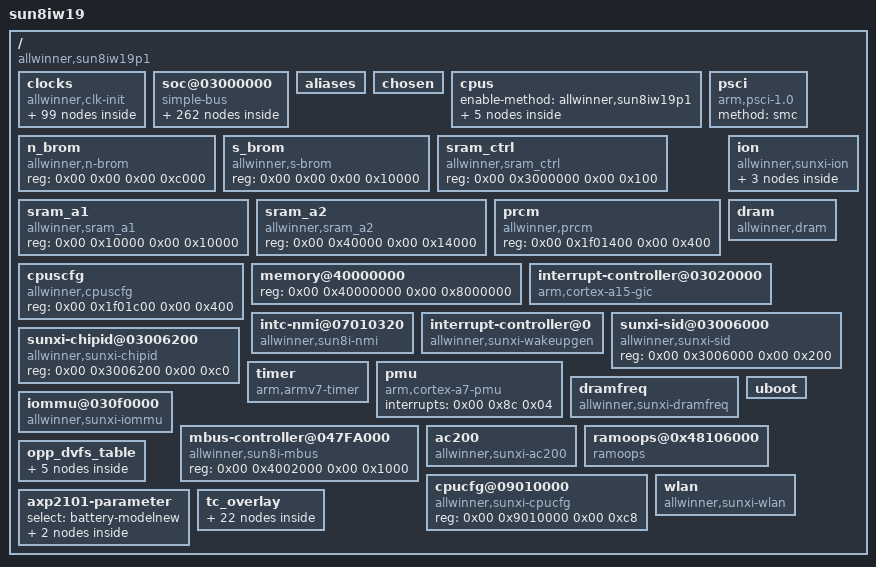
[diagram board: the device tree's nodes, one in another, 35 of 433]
/dts-v1/;

/memreserve/	0x0000000041980000 0x0000000000018000;
/ {
	model = "sun8iw19";
	compatible = "allwinner,sun8iw19p1";
	interrupt-parent = <0x01>;
	#address-cells = <0x02>;
	#size-cells = <0x02>;

	clocks {
		compatible = "allwinner,clk-init";
		device_type = "clocks";
		#address-cells = <0x02>;
		#size-cells = <0x02>;
		ranges;
		reg = <0x00 0x3001000 0x00 0x1000 0x00 0x7010000 0x00 0x400 0x00 0x7000000 0x00 0x200>;

		losc {
			#clock-cells = <0x00>;
			compatible = "allwinner,fixed-clock";
			clock-frequency = <0x8000>;
			clock-output-names = "losc";
			linux,phandle = <0x12>;
			phandle = <0x12>;
		};

		iosc {
			#clock-cells = <0x00>;
			compatible = "allwinner,fixed-clock";
			clock-frequency = <0xf42400>;
			clock-output-names = "iosc";
			linux,phandle = <0xb6>;
			phandle = <0xb6>;
		};

		hosc {
			#clock-cells = <0x00>;
			compatible = "allwinner,fixed-clock";
			clock-frequency = <0x16e3600>;
			clock-output-names = "hosc";
			linux,phandle = <0x08>;
			phandle = <0x08>;
		};

		pll_periph0div25m {
			#clock-cells = <0x00>;
			compatible = "allwinner,fixed-clock";
			clock-frequency = <0x17d7840>;
			clock-output-names = "pll_periph0div25m";
			linux,phandle = <0xb7>;
			phandle = <0xb7>;
		};

		osc48m {
			#clock-cells = <0x00>;
			compatible = "allwinner,fixed-clock";
			clock-frequency = <0x2dc6c00>;
			clock-output-names = "osc48m";
			linux,phandle = <0x09>;
			phandle = <0x09>;
		};

		pll_cpu {
			#clock-cells = <0x00>;
			compatible = "allwinner,pll-clock";
			lock-mode = "new";
			clock-output-names = "pll_cpu";
			linux,phandle = <0xaa>;
			phandle = <0xaa>;
		};

		pll_ddr0 {
			#clock-cells = <0x00>;
			compatible = "allwinner,pll-clock";
			lock-mode = "new";
			clock-output-names = "pll_ddr0";
			linux,phandle = <0x07>;
			phandle = <0x07>;
		};

		pll_periph0 {
			#clock-cells = <0x00>;
			compatible = "allwinner,pll-clock";
			assigned-clock-rates = <0x23c34600>;
			lock-mode = "new";
			clock-output-names = "pll_periph0";
			linux,phandle = <0x05>;
			phandle = <0x05>;
		};

		pll_uni {
			#clock-cells = <0x00>;
			compatible = "allwinner,pll-clock";
			assigned-clocks = <0x02>;
			assigned-clock-rates = <0x35a4e900>;
			lock-mode = "new";
			clock-output-names = "pll_uni";
			linux,phandle = <0x02>;
			phandle = <0x02>;
		};

		pll_video0 {
			#clock-cells = <0x00>;
			compatible = "allwinner,pll-clock";
			lock-mode = "new";
			clock-output-names = "pll_video0";
			linux,phandle = <0x06>;
			phandle = <0x06>;
		};

		pll_audio {
			#clock-cells = <0x00>;
			compatible = "allwinner,pll-clock";
			assigned-clocks = <0x03>;
			assigned-clock-rates = <0x1770000>;
			lock-mode = "new";
			clock-output-names = "pll_audio";
			linux,phandle = <0x03>;
			phandle = <0x03>;
		};

		pll_csi {
			#clock-cells = <0x00>;
			compatible = "allwinner,pll-clock";
			assigned-clocks = <0x04>;
			assigned-clock-rates = <0x202fbf00>;
			lock-mode = "new";
			clock-output-names = "pll_csi";
			linux,phandle = <0x04>;
			phandle = <0x04>;
		};

		pll_periph0x2 {
			#clock-cells = <0x00>;
			compatible = "allwinner,fixed-factor-clock";
			clocks = <0x05>;
			clock-mult = <0x02>;
			clock-div = <0x01>;
			clock-output-names = "pll_periph0x2";
			linux,phandle = <0x0e>;
			phandle = <0x0e>;
		};

		periph32k {
			#clock-cells = <0x00>;
			compatible = "allwinner,fixed-factor-clock";
			clocks = <0x05>;
			clock-mult = <0x02>;
			clock-div = <0x8f0d>;
			clock-output-names = "periph32k";
			linux,phandle = <0xb8>;
			phandle = <0xb8>;
		};

		pll_unix2 {
			#clock-cells = <0x00>;
			compatible = "allwinner,fixed-factor-clock";
			clocks = <0x02>;
			clock-mult = <0x02>;
			clock-div = <0x01>;
			clock-output-names = "pll_unix2";
			linux,phandle = <0x14>;
			phandle = <0x14>;
		};

		pll_audiox4 {
			#clock-cells = <0x00>;
			compatible = "allwinner,fixed-factor-clock";
			clocks = <0x03>;
			clock-mult = <0x04>;
			clock-div = <0x01>;
			clock-output-names = "pll_audiox4";
			linux,phandle = <0xb9>;
			phandle = <0xb9>;
		};

		pll_audiox2 {
			#clock-cells = <0x00>;
			compatible = "allwinner,fixed-factor-clock";
			clocks = <0x03>;
			clock-mult = <0x02>;
			clock-div = <0x01>;
			clock-output-names = "pll_audiox2";
			linux,phandle = <0xba>;
			phandle = <0xba>;
		};

		pll_video0x4 {
			#clock-cells = <0x00>;
			compatible = "allwinner,fixed-factor-clock";
			clocks = <0x06>;
			clock-mult = <0x04>;
			clock-div = <0x01>;
			clock-output-names = "pll_video0x4";
			linux,phandle = <0xbb>;
			phandle = <0xbb>;
		};

		mbus {
			#clock-cells = <0x00>;
			compatible = "allwinner,fixed-factor-clock";
			clocks = <0x07>;
			clock-mult = <0x01>;
			clock-div = <0x04>;
			clock-output-names = "mbus";
			linux,phandle = <0xbc>;
			phandle = <0xbc>;
		};

		hoscd2 {
			#clock-cells = <0x00>;
			compatible = "allwinner,fixed-factor-clock";
			clocks = <0x08>;
			clock-mult = <0x01>;
			clock-div = <0x02>;
			clock-output-names = "hoscd2";
			linux,phandle = <0xbd>;
			phandle = <0xbd>;
		};

		osc48md4 {
			#clock-cells = <0x00>;
			compatible = "allwinner,fixed-factor-clock";
			clocks = <0x09>;
			clock-mult = <0x01>;
			clock-div = <0x04>;
			clock-output-names = "osc48md4";
			linux,phandle = <0x45>;
			phandle = <0x45>;
		};

		cpu {
			#clock-cells = <0x00>;
			compatible = "allwinner,cpu-clock";
			clock-output-names = "cpu";
			linux,phandle = <0xbe>;
			phandle = <0xbe>;
		};

		axi {
			#clock-cells = <0x00>;
			compatible = "allwinner,periph-clock";
			clock-output-names = "axi";
			linux,phandle = <0xbf>;
			phandle = <0xbf>;
		};

		cpuapb {
			#clock-cells = <0x00>;
			compatible = "allwinner,periph-clock";
			clock-output-names = "cpuapb";
			linux,phandle = <0xc0>;
			phandle = <0xc0>;
		};

		psi {
			#clock-cells = <0x00>;
			compatible = "allwinner,periph-clock";
			clock-output-names = "psi";
			linux,phandle = <0xc1>;
			phandle = <0xc1>;
		};

		ahb1 {
			#clock-cells = <0x00>;
			compatible = "allwinner,periph-clock";
			clock-output-names = "ahb1";
			linux,phandle = <0xc2>;
			phandle = <0xc2>;
		};

		ahb2 {
			#clock-cells = <0x00>;
			compatible = "allwinner,periph-clock";
			clock-output-names = "ahb2";
			linux,phandle = <0xc3>;
			phandle = <0xc3>;
		};

		ahb3 {
			#clock-cells = <0x00>;
			compatible = "allwinner,periph-clock";
			clock-output-names = "ahb3";
			linux,phandle = <0xc4>;
			phandle = <0xc4>;
		};

		apb1 {
			#clock-cells = <0x00>;
			compatible = "allwinner,periph-clock";
			clock-output-names = "apb1";
			linux,phandle = <0xc5>;
			phandle = <0xc5>;
		};

		apb2 {
			#clock-cells = <0x00>;
			compatible = "allwinner,periph-clock";
			clock-output-names = "apb2";
			linux,phandle = <0xc6>;
			phandle = <0xc6>;
		};

		de {
			#clock-cells = <0x00>;
			compatible = "allwinner,periph-clock";
			assigned-clocks = <0x0a>;
			assigned-clock-rates = <0x11e1a300>;
			clock-output-names = "de";
			linux,phandle = <0x0a>;
			phandle = <0x0a>;
		};

		g2d {
			#clock-cells = <0x00>;
			compatible = "allwinner,periph-clock";
			assigned-clock-rates = <0x11e1a300>;
			assigned-clocks = <0x0b>;
			clock-output-names = "g2d";
			linux,phandle = <0x0b>;
			phandle = <0x0b>;
		};

		ve {
			#clock-cells = <0x00>;
			compatible = "allwinner,periph-clock";
			assigned-clock-rates = <0x1ad27480>;
			assigned-clocks = <0x0c>;
			clock-output-names = "ve";
			linux,phandle = <0x0c>;
			phandle = <0x0c>;
		};

		ce {
			#clock-cells = <0x00>;
			compatible = "allwinner,periph-clock";
			clock-output-names = "ce";
			linux,phandle = <0x9d>;
			phandle = <0x9d>;
		};

		eise {
			#clock-cells = <0x00>;
			compatible = "allwinner,periph-clock";
			clock-output-names = "eise";
			linux,phandle = <0x16>;
			phandle = <0x16>;
		};

		nna {
			#clock-cells = <0x00>;
			compatible = "allwinner,periph-clock";
			assigned-clocks = <0x0d>;
			assigned-clock-parents = <0x0e>;
			clock-output-names = "nna";
			linux,phandle = <0x0d>;
			phandle = <0x0d>;
		};

		nna_rts {
			#clock-cells = <0x00>;
			compatible = "allwinner,periph-clock";
			clock-output-names = "nna_rst";
			linux,phandle = <0x70>;
			phandle = <0x70>;
		};

		isp {
			#clock-cells = <0x00>;
			compatible = "allwinner,periph-clock";
			clock-output-names = "isp";
			linux,phandle = <0x93>;
			phandle = <0x93>;
		};

		dma {
			#clock-cells = <0x00>;
			compatible = "allwinner,periph-clock";
			clock-output-names = "dma";
			linux,phandle = <0x13>;
			phandle = <0x13>;
		};

		hstimer {
			#clock-cells = <0x00>;
			compatible = "allwinner,periph-clock";
			clock-output-names = "hstimer";
			linux,phandle = <0xc7>;
			phandle = <0xc7>;
		};

		avs {
			#clock-cells = <0x00>;
			compatible = "allwinner,periph-clock";
			clock-output-names = "avs";
			linux,phandle = <0xc8>;
			phandle = <0xc8>;
		};

		dbgsys {
			#clock-cells = <0x00>;
			compatible = "allwinner,periph-clock";
			clock-output-names = "dbgsys";
			linux,phandle = <0xc9>;
			phandle = <0xc9>;
		};

		pwm {
			#clock-cells = <0x00>;
			compatible = "allwinner,periph-clock";
			clock-output-names = "pwm";
			linux,phandle = <0x71>;
			phandle = <0x71>;
		};

		iommu {
			#clock-cells = <0x00>;
			compatible = "allwinner,periph-clock";
			clock-output-names = "iommu";
			linux,phandle = <0xb0>;
			phandle = <0xb0>;
		};

		sdram {
			#clock-cells = <0x00>;
			compatible = "allwinner,periph-clock";
			clock-output-names = "sdram";
			linux,phandle = <0xca>;
			phandle = <0xca>;
		};

		sdmmc0_mod {
			#clock-cells = <0x00>;
			compatible = "allwinner,periph-clock";
			clock-output-names = "sdmmc0_mod";
			linux,phandle = <0x62>;
			phandle = <0x62>;
		};

		sdmmc0_bus {
			#clock-cells = <0x00>;
			compatible = "allwinner,periph-clock";
			clock-output-names = "sdmmc0_bus";
			linux,phandle = <0x63>;
			phandle = <0x63>;
		};

		sdmmc0_rst {
			#clock-cells = <0x00>;
			compatible = "allwinner,periph-clock";
			clock-output-names = "sdmmc0_rst";
			linux,phandle = <0x64>;
			phandle = <0x64>;
		};

		sdmmc1_mod {
			#clock-cells = <0x00>;
			compatible = "allwinner,periph-clock";
			clock-output-names = "sdmmc1_mod";
			linux,phandle = <0x68>;
			phandle = <0x68>;
		};

		sdmmc1_bus {
			#clock-cells = <0x00>;
			compatible = "allwinner,periph-clock";
			clock-output-names = "sdmmc1_bus";
			linux,phandle = <0x69>;
			phandle = <0x69>;
		};

		sdmmc1_rst {
			#clock-cells = <0x00>;
			compatible = "allwinner,periph-clock";
			clock-output-names = "sdmmc1_rst";
			linux,phandle = <0x6a>;
			phandle = <0x6a>;
		};

		sdmmc2_mod {
			#clock-cells = <0x00>;
			compatible = "allwinner,periph-clock";
			clock-output-names = "sdmmc2_mod";
			linux,phandle = <0x5c>;
			phandle = <0x5c>;
		};

		sdmmc2_bus {
			#clock-cells = <0x00>;
			compatible = "allwinner,periph-clock";
			clock-output-names = "sdmmc2_bus";
			linux,phandle = <0x5d>;
			phandle = <0x5d>;
		};

		sdmmc2_rst {
			#clock-cells = <0x00>;
			compatible = "allwinner,periph-clock";
			clock-output-names = "sdmmc2_rst";
			linux,phandle = <0x5e>;
			phandle = <0x5e>;
		};

		uart0 {
			#clock-cells = <0x00>;
			compatible = "allwinner,periph-clock";
			clock-output-names = "uart0";
			linux,phandle = <0x17>;
			phandle = <0x17>;
		};

		uart1 {
			#clock-cells = <0x00>;
			compatible = "allwinner,periph-clock";
			clock-output-names = "uart1";
			linux,phandle = <0x1a>;
			phandle = <0x1a>;
		};

		uart2 {
			#clock-cells = <0x00>;
			compatible = "allwinner,periph-clock";
			clock-output-names = "uart2";
			linux,phandle = <0x1d>;
			phandle = <0x1d>;
		};

		uart3 {
			#clock-cells = <0x00>;
			compatible = "allwinner,periph-clock";
			clock-output-names = "uart3";
			linux,phandle = <0x20>;
			phandle = <0x20>;
		};

		twi0 {
			#clock-cells = <0x00>;
			compatible = "allwinner,periph-clock";
			clock-output-names = "twi0";
			linux,phandle = <0x26>;
			phandle = <0x26>;
		};

		twi1 {
			#clock-cells = <0x00>;
			compatible = "allwinner,periph-clock";
			clock-output-names = "twi1";
			linux,phandle = <0x29>;
			phandle = <0x29>;
		};

		twi2 {
			#clock-cells = <0x00>;
			compatible = "allwinner,periph-clock";
			clock-output-names = "twi2";
			linux,phandle = <0x2c>;
			phandle = <0x2c>;
		};

		twi3 {
			#clock-cells = <0x00>;
			compatible = "allwinner,periph-clock";
			clock-output-names = "twi3";
			linux,phandle = <0x2f>;
			phandle = <0x2f>;
		};

		spi0 {
			#clock-cells = <0x00>;
			compatible = "allwinner,periph-clock";
			clock-output-names = "spi0";
			linux,phandle = <0x50>;
			phandle = <0x50>;
		};

		spi1 {
			#clock-cells = <0x00>;
			compatible = "allwinner,periph-clock";
			clock-output-names = "spi1";
			linux,phandle = <0x54>;
			phandle = <0x54>;
		};

		spi2 {
			#clock-cells = <0x00>;
			compatible = "allwinner,periph-clock";
			clock-output-names = "spi2";
			linux,phandle = <0x58>;
			phandle = <0x58>;
		};

		ephy_25m {
			#clock-cells = <0x00>;
			compatible = "allwinner,periph-clock";
			clock-output-names = "ephy_25m";
			linux,phandle = <0xa7>;
			phandle = <0xa7>;
		};

		gmac {
			#clock-cells = <0x00>;
			compatible = "allwinner,periph-clock";
			clock-output-names = "gmac";
			linux,phandle = <0xa6>;
			phandle = <0xa6>;
		};

		gpadc {
			#clock-cells = <0x00>;
			compatible = "allwinner,periph-clock";
			clock-output-names = "gpadc";
			linux,phandle = <0xa5>;
			phandle = <0xa5>;
		};

		ths {
			#clock-cells = <0x00>;
			compatible = "allwinner,periph-clock";
			clock-output-names = "ths";
			linux,phandle = <0x9e>;
			phandle = <0x9e>;
		};

		i2s0 {
			#clock-cells = <0x00>;
			compatible = "allwinner,periph-clock";
			clock-output-names = "i2s0";
			linux,phandle = <0x46>;
			phandle = <0x46>;
		};

		i2s1 {
			#clock-cells = <0x00>;
			compatible = "allwinner,periph-clock";
			clock-output-names = "i2s1";
			linux,phandle = <0x49>;
			phandle = <0x49>;
		};

		codec_1x {
			#clock-cells = <0x00>;
			compatible = "allwinner,periph-clock";
			clock-output-names = "codec_1x";
			linux,phandle = <0x4c>;
			phandle = <0x4c>;
		};

		codec_4x {
			#clock-cells = <0x00>;
			compatible = "allwinner,periph-clock";
			clock-output-names = "codec_4x";
			linux,phandle = <0xcb>;
			phandle = <0xcb>;
		};

		usbphy0 {
			#clock-cells = <0x00>;
			compatible = "allwinner,periph-clock";
			clock-output-names = "usbphy0";
			linux,phandle = <0x40>;
			phandle = <0x40>;
		};

		usbohci0 {
			#clock-cells = <0x00>;
			compatible = "allwinner,periph-clock";
			clock-output-names = "usbohci0";
			linux,phandle = <0x43>;
			phandle = <0x43>;
		};

		usbohci0_12m {
			#clock-cells = <0x00>;
			compatible = "allwinner,periph-clock";
			clock-output-names = "usbohci0_12m";
			linux,phandle = <0x44>;
			phandle = <0x44>;
		};

		usbehci0 {
			#clock-cells = <0x00>;
			compatible = "allwinner,periph-clock";
			clock-output-names = "usbehci0";
			linux,phandle = <0x42>;
			phandle = <0x42>;
		};

		usbotg {
			#clock-cells = <0x00>;
			compatible = "allwinner,periph-clock";
			clock-output-names = "usbotg";
			linux,phandle = <0x41>;
			phandle = <0x41>;
		};

		mipi_dphy0 {
			#clock-cells = <0x00>;
			compatible = "allwinner,periph-clock";
			clock-output-names = "mipi_dphy0";
			linux,phandle = <0x6f>;
			phandle = <0x6f>;
		};

		mipi_host0 {
			#clock-cells = <0x00>;
			compatible = "allwinner,periph-clock";
			assigned-clocks = <0x0f>;
			assigned-clock-parents = <0x08>;
			clock-output-names = "mipi_host0";
			linux,phandle = <0x0f>;
			phandle = <0x0f>;
		};

		display_top {
			#clock-cells = <0x00>;
			compatible = "allwinner,periph-clock";
			clock-output-names = "display_top";
			linux,phandle = <0x6d>;
			phandle = <0x6d>;
		};

		tcon_lcd {
			#clock-cells = <0x00>;
			compatible = "allwinner,periph-clock";
			clock-output-names = "tcon_lcd";
			linux,phandle = <0x6e>;
			phandle = <0x6e>;
		};

		csi_top {
			#clock-cells = <0x00>;
			compatible = "allwinner,periph-clock";
			clock-output-names = "csi_top";
			linux,phandle = <0x90>;
			phandle = <0x90>;
		};

		csi_master0 {
			#clock-cells = <0x00>;
			compatible = "allwinner,periph-clock";
			clock-output-names = "csi_master0";
			linux,phandle = <0x91>;
			phandle = <0x91>;
		};

		csi_master1 {
			#clock-cells = <0x00>;
			compatible = "allwinner,periph-clock";
			clock-output-names = "csi_master1";
			linux,phandle = <0x92>;
			phandle = <0x92>;
		};

		dspo {
			#clock-cells = <0x00>;
			compatible = "allwinner,periph-clock";
			clock-output-names = "dspo";
			linux,phandle = <0xcc>;
			phandle = <0xcc>;
		};

		pio {
			#clock-cells = <0x00>;
			compatible = "allwinner,periph-clock";
			clock-output-names = "pio";
			linux,phandle = <0x11>;
			phandle = <0x11>;
		};

		cpurowc {
			#clock-cells = <0x00>;
			compatible = "allwinner,periph-cpus-clock";
			clock-output-names = "cpurowc";
			linux,phandle = <0x23>;
			phandle = <0x23>;
		};

		stwi {
			#clock-cells = <0x00>;
			compatible = "allwinner,periph-cpus-clock";
			clock-output-names = "stwi";
			linux,phandle = <0x32>;
			phandle = <0x32>;
		};

		losc_out {
			#clock-cells = <0x00>;
			compatible = "allwinner,periph-cpus-clock";
			clock-output-names = "losc_out";
			linux,phandle = <0xcd>;
			phandle = <0xcd>;
		};

		cpurcpus_pll {
			#clock-cells = <0x00>;
			compatible = "allwinner,periph-cpus-clock";
			clock-output-names = "cpurcpus_pll";
			linux,phandle = <0xce>;
			phandle = <0xce>;
		};

		cpurcpus {
			#clock-cells = <0x00>;
			compatible = "allwinner,periph-cpus-clock";
			clock-output-names = "cpurcpus";
			linux,phandle = <0xcf>;
			phandle = <0xcf>;
		};

		cpurahbs {
			#clock-cells = <0x00>;
			compatible = "allwinner,periph-cpus-clock";
			clock-output-names = "cpurahbs";
			linux,phandle = <0xd0>;
			phandle = <0xd0>;
		};

		cpurapbs1 {
			#clock-cells = <0x00>;
			compatible = "allwinner,periph-cpus-clock";
			clock-output-names = "cpurapbs1";
			linux,phandle = <0xd1>;
			phandle = <0xd1>;
		};

		cpurapbs2_pll {
			#clock-cells = <0x00>;
			compatible = "allwinner,periph-cpus-clock";
			clock-output-names = "cpurapbs2_pll";
			linux,phandle = <0xd2>;
			phandle = <0xd2>;
		};

		cpurapbs2 {
			#clock-cells = <0x00>;
			compatible = "allwinner,periph-cpus-clock";
			clock-output-names = "cpurapbs2";
			linux,phandle = <0xd3>;
			phandle = <0xd3>;
		};

		cpurpio {
			#clock-cells = <0x00>;
			compatible = "allwinner,periph-cpus-clock";
			clock-output-names = "cpurpio";
			linux,phandle = <0x10>;
			phandle = <0x10>;
		};

		spwm {
			#clock-cells = <0x00>;
			compatible = "allwinner,periph-cpus-clock";
			clock-output-names = "spwm";
			linux,phandle = <0xd4>;
			phandle = <0xd4>;
		};

		dcxo_out {
			#clock-cells = <0x00>;
			compatible = "allwinner,periph-cpus-clock";
			clock-output-names = "dcxo_out";
			linux,phandle = <0xb1>;
			phandle = <0xb1>;
		};
	};

	soc@03000000 {
		compatible = "simple-bus";
		#address-cells = <0x02>;
		#size-cells = <0x02>;
		ranges;
		device_type = "soc";
		linux,phandle = <0xb4>;
		phandle = <0xb4>;

		pinctrl@07022000 {
			compatible = "allwinner,sun8iw19p1-r-pinctrl";
			reg = <0x00 0x7022000 0x00 0x400>;
			interrupts = <0x00 0x6a 0x04>;
			clocks = <0x10>;
			device_type = "r_pio";
			gpio-controller;
			interrupt-controller;
			#interrupt-cells = <0x03>;
			#size-cells = <0x00>;
			#gpio-cells = <0x06>;
			linux,phandle = <0xd5>;
			phandle = <0xd5>;

			s_twi0@0 {
				allwinner,pins = "PL0\0PL1";
				allwinner,function = "s_twi0";
				allwinner,muxsel = <0x03>;
				allwinner,drive = <0x01>;
				allwinner,pull = <0x01>;
				linux,phandle = <0x33>;
				phandle = <0x33>;
			};

			s_twi0@1 {
				allwinner,pins = "PL0\0PL1";
				allwinner,function = "io_disabled";
				allwinner,muxsel = <0x07>;
				allwinner,drive = <0x01>;
				allwinner,pull = <0x00>;
				linux,phandle = <0x34>;
				phandle = <0x34>;
			};
		};

		pinctrl@0300b000 {
			compatible = "allwinner,sun8iw19p1-pinctrl";
			reg = <0x00 0x300b000 0x00 0x400>;
			interrupts = <0x00 0x43 0x04 0x00 0x44 0x04 0x00 0x45 0x04 0x00 0x46 0x04 0x00 0x47 0x04 0x00 0x48 0x04 0x00 0x49 0x04>;
			device_type = "pio";
			clocks = <0x11 0x12 0x08>;
			gpio-controller;
			interrupt-controller;
			#interrupt-cells = <0x03>;
			#size-cells = <0x00>;
			#gpio-cells = <0x06>;
			input-debounce = <0x00 0x00 0x00 0x01 0x00 0x00 0x00>;
			linux,phandle = <0x36>;
			phandle = <0x36>;

			vdevice@0 {
				allwinner,pins = "PC0\0PC1";
				allwinner,function = "vdevice";
				allwinner,muxsel = <0x05>;
				allwinner,drive = <0x01>;
				allwinner,pull = <0x01>;
				linux,phandle = <0x9c>;
				phandle = <0x9c>;
			};

			uart0@0 {
				allwinner,pins = "PH9\0PH10";
				allwinner,pname = "uart0_tx\0uart0_rx";
				allwinner,function = "uart0";
				allwinner,muxsel = <0x05>;
				allwinner,drive = <0x01>;
				allwinner,pull = <0x01>;
				linux,phandle = <0x18>;
				phandle = <0x18>;
			};

			uart0@1 {
				allwinner,pins = "PH9\0PH10";
				allwinner,function = "io_disabled";
				allwinner,muxsel = <0x07>;
				allwinner,drive = <0x01>;
				allwinner,pull = <0x00>;
				linux,phandle = <0x19>;
				phandle = <0x19>;
			};

			uart1@0 {
				allwinner,pins = "PG6\0PG7\0PG4\0PG5";
				allwinner,pname = "uart1_tx\0uart1_rx\0uart1_rts\0uart1_cts";
				allwinner,function = "uart1";
				allwinner,muxsel = <0x05>;
				allwinner,drive = <0x01>;
				allwinner,pull = <0x01>;
				linux,phandle = <0x1b>;
				phandle = <0x1b>;
			};

			uart1@1 {
				allwinner,pins = "PG6\0PG7\0PG4\0PG5";
				allwinner,function = "io_disabled";
				allwinner,muxsel = <0x07>;
				allwinner,drive = <0x01>;
				allwinner,pull = <0x00>;
				linux,phandle = <0x1c>;
				phandle = <0x1c>;
			};

			uart3@0 {
				allwinner,pins = "PG0\0PG1\0PG2\0PG3";
				allwinner,pname = "uart3_tx\0uart3_rx\0uart3_rts\0uart3_cts";
				allwinner,function = "uart3";
				allwinner,muxsel = <0x05>;
				allwinner,drive = <0x01>;
				allwinner,pull = <0x01>;
				linux,phandle = <0x21>;
				phandle = <0x21>;
			};

			uart3@1 {
				allwinner,pins = "PG0\0PG1\0PG2\0PG3";
				allwinner,function = "io_disabled";
				allwinner,muxsel = <0x07>;
				allwinner,drive = <0x01>;
				allwinner,pull = <0x00>;
				linux,phandle = <0x22>;
				phandle = <0x22>;
			};

			twi0@0 {
				allwinner,pins = "PE16\0PE17";
				allwinner,pname = "twi0_scl\0twi0_sda";
				allwinner,function = "twi0";
				allwinner,muxsel = <0x05>;
				allwinner,drive = <0x01>;
				allwinner,pull = <0x00>;
				linux,phandle = <0x27>;
				phandle = <0x27>;
			};

			twi0@1 {
				allwinner,pins = "PE16\0PE17";
				allwinner,function = "io_disabled";
				allwinner,muxsel = <0x07>;
				allwinner,drive = <0x01>;
				allwinner,pull = <0x00>;
				linux,phandle = <0x28>;
				phandle = <0x28>;
			};

			twi1@0 {
				allwinner,pins = "PI1\0PI2";
				allwinner,pname = "twi1_scl\0twi1_sda";
				allwinner,function = "twi1";
				allwinner,muxsel = <0x05>;
				allwinner,drive = <0x01>;
				allwinner,pull = <0x00>;
				linux,phandle = <0x2a>;
				phandle = <0x2a>;
			};

			twi1@1 {
				allwinner,pins = "PI1\0PI2";
				allwinner,function = "io_disabled";
				allwinner,muxsel = <0x07>;
				allwinner,drive = <0x01>;
				allwinner,pull = <0x00>;
				linux,phandle = <0x2b>;
				phandle = <0x2b>;
			};

			twi2@0 {
				allwinner,pins = "PH11\0PH12";
				allwinner,pname = "twi2_scl\0twi2_sda";
				allwinner,function = "twi2";
				allwinner,muxsel = <0x05>;
				allwinner,drive = <0x01>;
				allwinner,pull = <0x00>;
				linux,phandle = <0x2d>;
				phandle = <0x2d>;
			};

			twi2@1 {
				allwinner,pins = "PH11\0PH12";
				allwinner,function = "io_disabled";
				allwinner,muxsel = <0x07>;
				allwinner,drive = <0x01>;
				allwinner,pull = <0x00>;
				linux,phandle = <0x2e>;
				phandle = <0x2e>;
			};

			twi3@0 {
				allwinner,pins = "PH13\0PH14";
				allwinner,pname = "twi3_scl\0twi3_sda";
				allwinner,function = "twi3";
				allwinner,muxsel = <0x05>;
				allwinner,drive = <0x01>;
				allwinner,pull = <0x00>;
				linux,phandle = <0x30>;
				phandle = <0x30>;
			};

			twi3@1 {
				allwinner,pins = "PH13\0PH14";
				allwinner,function = "io_disabled";
				allwinner,muxsel = <0x07>;
				allwinner,drive = <0x01>;
				allwinner,pull = <0x00>;
				linux,phandle = <0x31>;
				phandle = <0x31>;
			};

			pwm0@0 {
				allwinner,pins = "PD1";
				allwinner,pname = "pwm0_positive";
				allwinner,function = "pwm0";
				allwinner,muxsel = <0x03>;
				allwinner,drive = <0x01>;
				allwinner,pull = <0x00>;
				linux,phandle = <0x7c>;
				phandle = <0x7c>;
			};

			pwm0@1 {
				allwinner,pins = "PD1";
				allwinner,function = "io_disabled";
				allwinner,muxsel = <0x07>;
				allwinner,drive = <0x01>;
				allwinner,pull = <0x00>;
				linux,phandle = <0x7d>;
				phandle = <0x7d>;
			};

			pwm1@0 {
				allwinner,pins = "PD2";
				allwinner,pname = "pwm1_positive";
				allwinner,function = "pwm1";
				allwinner,muxsel = <0x03>;
				allwinner,drive = <0x01>;
				allwinner,pull = <0x00>;
				linux,phandle = <0x7e>;
				phandle = <0x7e>;
			};

			pwm1@1 {
				allwinner,pins = "PD2";
				allwinner,function = "io_disabled";
				allwinner,muxsel = <0x07>;
				allwinner,drive = <0x01>;
				allwinner,pull = <0x00>;
				linux,phandle = <0x7f>;
				phandle = <0x7f>;
			};

			pwm2@0 {
				allwinner,pins = "PD3";
				allwinner,pname = "pwm2_positive";
				allwinner,function = "pwm2";
				allwinner,muxsel = <0x03>;
				allwinner,drive = <0x01>;
				allwinner,pull = <0x00>;
				linux,phandle = <0x80>;
				phandle = <0x80>;
			};

			pwm2@1 {
				allwinner,pins = "PD3";
				allwinner,function = "io_disabled";
				allwinner,muxsel = <0x07>;
				allwinner,drive = <0x01>;
				allwinner,pull = <0x00>;
				linux,phandle = <0x81>;
				phandle = <0x81>;
			};

			pwm3@0 {
				allwinner,pins = "PD4";
				allwinner,pname = "pwm3_positive";
				allwinner,function = "pwm3";
				allwinner,muxsel = <0x03>;
				allwinner,drive = <0x01>;
				allwinner,pull = <0x00>;
				linux,phandle = <0x82>;
				phandle = <0x82>;
			};

			pwm3@1 {
				allwinner,pins = "PD4";
				allwinner,function = "io_disabled";
				allwinner,muxsel = <0x07>;
				allwinner,drive = <0x01>;
				allwinner,pull = <0x00>;
				linux,phandle = <0x83>;
				phandle = <0x83>;
			};

			pwm4@0 {
				allwinner,pins = "PD5";
				allwinner,pname = "pwm4_positive";
				allwinner,function = "pwm4";
				allwinner,muxsel = <0x03>;
				allwinner,drive = <0x01>;
				allwinner,pull = <0x00>;
				linux,phandle = <0x84>;
				phandle = <0x84>;
			};

			pwm4@1 {
				allwinner,pins = "PD5";
				allwinner,function = "io_disabled";
				allwinner,muxsel = <0x07>;
				allwinner,drive = <0x01>;
				allwinner,pull = <0x00>;
				linux,phandle = <0x85>;
				phandle = <0x85>;
			};

			pwm5@0 {
				allwinner,pins = "PD6";
				allwinner,pname = "pwm5_positive";
				allwinner,function = "pwm5";
				allwinner,muxsel = <0x03>;
				allwinner,drive = <0x01>;
				allwinner,pull = <0x00>;
				linux,phandle = <0x86>;
				phandle = <0x86>;
			};

			pwm5@1 {
				allwinner,pins = "PD6";
				allwinner,function = "io_disabled";
				allwinner,muxsel = <0x07>;
				allwinner,drive = <0x01>;
				allwinner,pull = <0x00>;
				linux,phandle = <0x87>;
				phandle = <0x87>;
			};

			pwm6@0 {
				allwinner,pins = "PD7";
				allwinner,pname = "pwm6_positive";
				allwinner,function = "pwm6";
				allwinner,muxsel = <0x03>;
				allwinner,drive = <0x01>;
				allwinner,pull = <0x00>;
				linux,phandle = <0x88>;
				phandle = <0x88>;
			};

			pwm6@1 {
				allwinner,pins = "PD7";
				allwinner,function = "io_disabled";
				allwinner,muxsel = <0x07>;
				allwinner,drive = <0x01>;
				allwinner,pull = <0x00>;
				linux,phandle = <0x89>;
				phandle = <0x89>;
			};

			pwm7@0 {
				allwinner,pins = "PD8";
				allwinner,pname = "pwm7_positive";
				allwinner,function = "pwm7";
				allwinner,muxsel = <0x03>;
				allwinner,drive = <0x01>;
				allwinner,pull = <0x00>;
				linux,phandle = <0x8a>;
				phandle = <0x8a>;
			};

			pwm7@1 {
				allwinner,pins = "PD8";
				allwinner,function = "io_disabled";
				allwinner,muxsel = <0x07>;
				allwinner,drive = <0x01>;
				allwinner,pull = <0x00>;
				linux,phandle = <0x8b>;
				phandle = <0x8b>;
			};

			pwm8@0 {
				allwinner,pins = "PD9";
				allwinner,pname = "pwm8_positive";
				allwinner,function = "pwm8";
				allwinner,muxsel = <0x03>;
				allwinner,drive = <0x01>;
				allwinner,pull = <0x00>;
				linux,phandle = <0x8c>;
				phandle = <0x8c>;
			};

			pwm8@1 {
				allwinner,pins = "PD9";
				allwinner,function = "io_disabled";
				allwinner,muxsel = <0x07>;
				allwinner,drive = <0x01>;
				allwinner,pull = <0x00>;
				linux,phandle = <0x8d>;
				phandle = <0x8d>;
			};

			pwm9@0 {
				allwinner,pins = "PD22";
				allwinner,pname = "pwm9_positive";
				allwinner,function = "pwm9";
				allwinner,muxsel = <0x02>;
				allwinner,drive = <0x01>;
				allwinner,pull = <0x00>;
				linux,phandle = <0x8e>;
				phandle = <0x8e>;
			};

			pwm9@1 {
				allwinner,pins = "PD22";
				allwinner,function = "io_disabled";
				allwinner,muxsel = <0x07>;
				allwinner,drive = <0x01>;
				allwinner,pull = <0x00>;
				linux,phandle = <0x8f>;
				phandle = <0x8f>;
			};

			ts0@0 {
				allwinner,pins = "PE0\0PE1\0PE2\0PE3\0PE4\0PE5\0PE6\0PE7\0PE8\0PE9\0PE10\0PE11";
				allwinner,pname = "ts0_clk\0ts0_err\0ts0_sync\0ts0_dvld\0ts0_d0\0ts0_d1\0ts0_d2\0ts0_d3\0ts0_d4\0ts0_d5\0ts0_d6\0ts0_d7";
				allwinner,function = "ts0";
				allwinner,muxsel = <0x03>;
				allwinner,drive = <0x01>;
				allwinner,pull = <0x00>;
				linux,phandle = <0xd6>;
				phandle = <0xd6>;
			};

			ts0_sleep@0 {
				allwinner,pins = "PE0\0PE1\0PE2\0PE3\0PE4\0PE5\0PE6\0PE7\0PE8\0PE9\0PE10\0PE11";
				allwinner,pname = "ts0_clk\0ts0_err\0ts0_sync\0ts0_dvld\0ts0_d0\0ts0_d1\0ts0_d2\0ts0_d3\0ts0_d4\0ts0_d5\0ts0_d6\0ts0_d7";
				allwinner,function = "io_disabled";
				allwinner,muxsel = <0x07>;
				allwinner,drive = <0x01>;
				allwinner,pull = <0x00>;
				linux,phandle = <0xd7>;
				phandle = <0xd7>;
			};

			ts1@0 {
				allwinner,pins = "PE7\0PE8\0PE9\0PE10\0PE11";
				allwinner,pname = "ts1_clk\0ts1_err\0ts1_sync\0ts1_dvld\0ts1_d0";
				allwinner,function = "ts1";
				allwinner,muxsel = <0x04>;
				allwinner,drive = <0x01>;
				allwinner,pull = <0x00>;
				linux,phandle = <0xd8>;
				phandle = <0xd8>;
			};

			ts1_sleep@0 {
				allwinner,pins = "PE7\0PE8\0PE9\0PE10\0PE11";
				allwinner,pname = "ts1_clk\0ts1_err\0ts1_sync\0ts1_dvld\0ts1_d0";
				allwinner,function = "io_disabled";
				allwinner,muxsel = <0x07>;
				allwinner,drive = <0x01>;
				allwinner,pull = <0x00>;
				linux,phandle = <0xd9>;
				phandle = <0xd9>;
			};

			ts2@0 {
				allwinner,pins = "PD0\0PD1\0PD2\0PD3\0PD4\0PD5\0PD6\0PD7\0PD8\0PD9\0PD10\0PD11";
				allwinner,pname = "ts2_clk\0ts2_err\0ts2_sync\0ts2_dvld\0ts2_d0\0ts2_d1\0ts2_d2\0ts2_d3\0ts2_d4\0ts2_d5\0ts2_d6\0ts2_d7";
				allwinner,function = "ts2";
				allwinner,muxsel = <0x04>;
				allwinner,drive = <0x01>;
				allwinner,pull = <0x00>;
				linux,phandle = <0xda>;
				phandle = <0xda>;
			};

			ts2_sleep@0 {
				allwinner,pins = "PD0\0PD1\0PD2\0PD3\0PD4\0PD5\0PD6\0PD7\0PD8\0PD9\0PD10\0PD11";
				allwinner,pname = "ts2_clk\0ts2_err\0ts2_sync\0ts2_dvld\0ts2_d0\0ts2_d1\0ts2_d2\0ts2_d3\0ts2_d4\0ts2_d5\0ts2_d6\0ts2_d7";
				allwinner,function = "io_disabled";
				allwinner,muxsel = <0x07>;
				allwinner,drive = <0x01>;
				allwinner,pull = <0x00>;
				linux,phandle = <0xdb>;
				phandle = <0xdb>;
			};

			ts3@0 {
				allwinner,pins = "PD7\0PD8\0PD9\0PD10\0PD11";
				allwinner,pname = "ts3_clk\0ts3_err\0ts3_sync\0ts3_dvld\0ts3_d0";
				allwinner,function = "ts3";
				allwinner,muxsel = <0x05>;
				allwinner,drive = <0x01>;
				allwinner,pull = <0x00>;
				linux,phandle = <0xdc>;
				phandle = <0xdc>;
			};

			ts3_sleep@0 {
				allwinner,pins = "PD7\0PD8\0PD9\0PD10\0PD11";
				allwinner,pname = "ts3_clk\0ts3_err\0ts3_sync\0ts3_dvld\0ts3_d0";
				allwinner,function = "io_disabled";
				allwinner,muxsel = <0x07>;
				allwinner,drive = <0x01>;
				allwinner,pull = <0x00>;
				linux,phandle = <0xdd>;
				phandle = <0xdd>;
			};

			spi0@0 {
				allwinner,pins = "PC0\0PC2\0PC3\0PC5\0PC4";
				allwinner,pname = "spi0_sclk\0spi0_mosi\0spi0_miso\0spi0_hold\0spi0_wp";
				allwinner,function = "spi0";
				allwinner,muxsel = <0x04>;
				allwinner,drive = <0x01>;
				allwinner,pull = <0x00>;
				linux,phandle = <0x51>;
				phandle = <0x51>;
			};

			spi0@1 {
				allwinner,pins = "PC1\0PC6";
				allwinner,pname = "spi0_cs0\0spi0_cs1";
				allwinner,function = "spi0";
				allwinner,muxsel = <0x04>;
				allwinner,drive = <0x01>;
				allwinner,pull = <0x01>;
				linux,phandle = <0x52>;
				phandle = <0x52>;
			};

			spi0@2 {
				allwinner,pins = "PC0\0PC1\0PC2\0PC3\0PC4\0PC5\0PC6";
				allwinner,function = "io_disabled";
				allwinner,muxsel = <0x07>;
				allwinner,drive = <0x01>;
				allwinner,pull = <0x00>;
				linux,phandle = <0x53>;
				phandle = <0x53>;
			};

			spi1@0 {
				allwinner,pins = "PH1\0PH2";
				allwinner,pname = "spi1_sclk\0spi1_mosi\0spi1_miso";
				allwinner,function = "spi1";
				allwinner,muxsel = <0x04>;
				allwinner,drive = <0x01>;
				allwinner,pull = <0x00>;
				linux,phandle = <0x55>;
				phandle = <0x55>;
			};

			spi1@1 {
				allwinner,pins = "PH3\0PH4";
				allwinner,pname = "spi1_cs0\0spi1_cs1";
				allwinner,function = "spi1";
				allwinner,muxsel = <0x04>;
				allwinner,drive = <0x01>;
				allwinner,pull = <0x01>;
				linux,phandle = <0x56>;
				phandle = <0x56>;
			};

			spi1@2 {
				allwinner,pins = "PH1\0PH2\0PH3\0PH4";
				allwinner,function = "io_disabled";
				allwinner,muxsel = <0x07>;
				allwinner,drive = <0x01>;
				allwinner,pull = <0x00>;
				linux,phandle = <0x57>;
				phandle = <0x57>;
			};

			spi2@0 {
				allwinner,pins = "PE18\0PE19\0PE20";
				allwinner,pname = "spi2_sclk\0spi2_mosi\0spi2_miso";
				allwinner,function = "spi2";
				allwinner,muxsel = <0x04>;
				allwinner,drive = <0x01>;
				allwinner,pull = <0x00>;
				linux,phandle = <0x59>;
				phandle = <0x59>;
			};

			spi2@1 {
				allwinner,pins = "PE21";
				allwinner,pname = "spi2_cs0";
				allwinner,function = "spi2";
				allwinner,muxsel = <0x04>;
				allwinner,drive = <0x01>;
				allwinner,pull = <0x01>;
				linux,phandle = <0x5a>;
				phandle = <0x5a>;
			};

			spi2@2 {
				allwinner,pins = "PE18\0PE19\0PE20\0PE21";
				allwinner,function = "io_disabled";
				allwinner,muxsel = <0x07>;
				allwinner,drive = <0x01>;
				allwinner,pull = <0x00>;
				linux,phandle = <0x5b>;
				phandle = <0x5b>;
			};

			spi3@0 {
				allwinner,pins = "PI3\0PI4\0PI5";
				allwinner,pname = "spi3_sclk\0spi3_mosi\0spi3_miso";
				allwinner,function = "spi3";
				allwinner,muxsel = <0x04>;
				allwinner,drive = <0x01>;
				allwinner,pull = <0x00>;
				linux,phandle = <0xde>;
				phandle = <0xde>;
			};

			spi3@1 {
				allwinner,pins = "PI6";
				allwinner,pname = "spi3_cs0";
				allwinner,function = "spi3";
				allwinner,muxsel = <0x04>;
				allwinner,drive = <0x01>;
				allwinner,pull = <0x01>;
				linux,phandle = <0xdf>;
				phandle = <0xdf>;
			};

			spi3@2 {
				allwinner,pins = "PI3\0PI4\0PI5\0PI6";
				allwinner,function = "io_disabled";
				allwinner,muxsel = <0x07>;
				allwinner,drive = <0x01>;
				allwinner,pull = <0x00>;
				linux,phandle = <0xe0>;
				phandle = <0xe0>;
			};

			sdc0@0 {
				allwinner,pins = "PF0\0PF1\0PF2\0PF3\0PF4\0PF5";
				allwinner,function = "sdc0";
				allwinner,muxsel = <0x02>;
				allwinner,drive = <0x03>;
				allwinner,pull = <0x01>;
				linux,phandle = <0x65>;
				phandle = <0x65>;
			};

			sdc0@1 {
				allwinner,pins = "PF0\0PF1\0PF2\0PF3\0PF4\0PF5";
				allwinner,function = "io_disabled";
				allwinner,muxsel = <0x07>;
				allwinner,drive = <0x01>;
				allwinner,pull = <0x02>;
				linux,phandle = <0x66>;
				phandle = <0x66>;
			};

			sdc0@2 {
				allwinner,pins = "PF0\0PF1\0PF2\0PF3\0PF4\0PF5";
				allwinner,function = "uart0_jtag";
				allwinner,muxsel = <0x03>;
				allwinner,drive = <0x01>;
				allwinner,pull = <0x02>;
				linux,phandle = <0x67>;
				phandle = <0x67>;
			};

			sdc1@0 {
				allwinner,pins = "PG0\0PG1\0PG2\0PG3\0PG4\0PG5";
				allwinner,function = "sdc1";
				allwinner,muxsel = <0x02>;
				allwinner,drive = <0x03>;
				allwinner,pull = <0x01>;
				linux,phandle = <0x6b>;
				phandle = <0x6b>;
			};

			sdc1@1 {
				allwinner,pins = "PG0\0PG1\0PG2\0PG3\0PG4\0PG5";
				allwinner,function = "io_disabled";
				allwinner,muxsel = <0x07>;
				allwinner,drive = <0x01>;
				allwinner,pull = <0x01>;
				linux,phandle = <0x6c>;
				phandle = <0x6c>;
			};

			sdc2@0 {
				allwinner,pins = "PC0\0PC1\0PC2\0PC3\0PC4\0PC5\0PC6\0PC7\0PC8\0PC9\0PC10\0PC11";
				allwinner,function = "sdc2";
				allwinner,muxsel = <0x03>;
				allwinner,drive = <0x03>;
				allwinner,pull = <0x01>;
				linux,phandle = <0x5f>;
				phandle = <0x5f>;
			};

			sdc2@1 {
				allwinner,pins = "PC11\0PC1\0PC2\0PC3\0PC4\0PC5\0PC6\0PC7\0PC8\0PC9\0PC10";
				allwinner,function = "io_disabled";
				allwinner,muxsel = <0x07>;
				allwinner,drive = <0x01>;
				allwinner,pull = <0x01>;
				linux,phandle = <0x61>;
				phandle = <0x61>;
			};

			sdc2@2 {
				allwinner,pins = "PC0";
				allwinner,function = "sdc2";
				allwinner,muxsel = <0x03>;
				allwinner,drive = <0x02>;
				allwinner,pull = <0x02>;
				linux,phandle = <0x60>;
				phandle = <0x60>;
			};

			aif2@0 {
				allwinner,pins = "PH1\0PH2\0PH3\0PH4";
				allwinner,function = "aif2";
				allwinner,muxsel = <0x02>;
				allwinner,drive = <0x01>;
				allwinner,pull = <0x00>;
				linux,phandle = <0xe1>;
				phandle = <0xe1>;
			};

			aif3@0 {
				allwinner,pins = "PG10\0PG11\0PG12\0PG13";
				allwinner,function = "aif3";
				allwinner,muxsel = <0x02>;
				allwinner,drive = <0x01>;
				allwinner,pull = <0x00>;
				linux,phandle = <0xe2>;
				phandle = <0xe2>;
			};

			aif2_sleep@0 {
				allwinner,pins = "PH1\0PH2\0PH3\0PH4";
				allwinner,function = "io_disabled";
				allwinner,muxsel = <0x07>;
				allwinner,drive = <0x01>;
				allwinner,pull = <0x00>;
				linux,phandle = <0xe3>;
				phandle = <0xe3>;
			};

			aif3_sleep@0 {
				allwinner,pins = "PG10\0PG11\0PG12\0PG13";
				allwinner,function = "io_disabled";
				allwinner,muxsel = <0x07>;
				allwinner,drive = <0x01>;
				allwinner,pull = <0x00>;
				linux,phandle = <0xe4>;
				phandle = <0xe4>;
			};

			owc0@0 {
				allwinner,pins = "PH4";
				allwinner,pname = "owc0";
				allwinner,function = "owc0";
				allwinner,muxsel = <0x05>;
				allwinner,drive = <0x01>;
				allwinner,pull = <0x00>;
				linux,phandle = <0x24>;
				phandle = <0x24>;
			};

			owc0_sleep@0 {
				allwinner,pins = "PH4";
				allwinner,function = "io_disabled";
				allwinner,muxsel = <0x07>;
				allwinner,drive = <0x01>;
				allwinner,pull = <0x00>;
				linux,phandle = <0x25>;
				phandle = <0x25>;
			};

			daudio0@0 {
				allwinner,pins = "PH1\0PH2\0PH3\0PH4";
				allwinner,function = "i2s0";
				allwinner,muxsel = <0x03>;
				allwinner,drive = <0x01>;
				allwinner,pull = <0x00>;
				linux,phandle = <0x47>;
				phandle = <0x47>;
			};

			daudio0_sleep@0 {
				allwinner,pins = "PH1\0PH2\0PH3\0PH4";
				allwinner,function = "io_disabled";
				allwinner,muxsel = <0x07>;
				allwinner,drive = <0x01>;
				allwinner,pull = <0x00>;
				linux,phandle = <0x48>;
				phandle = <0x48>;
			};

			daudio1@0 {
				allwinner,pins = "PD10\0PD11\0PD12\0PD13\0PD14\0PD15\0PD16\0PD17";
				allwinner,function = "i2s1";
				allwinner,muxsel = <0x03>;
				allwinner,drive = <0x01>;
				allwinner,pull = <0x00>;
				linux,phandle = <0x4a>;
				phandle = <0x4a>;
			};

			daudio1_sleep@0 {
				allwinner,pins = "PD10\0PD11\0PD12\0PD13\0PD14\0PD15\0PD16\0PD17";
				allwinner,function = "io_disabled";
				allwinner,muxsel = <0x07>;
				allwinner,drive = <0x01>;
				allwinner,pull = <0x00>;
				linux,phandle = <0x4b>;
				phandle = <0x4b>;
			};

			csi_mclk0@0 {
				allwinner,pins = "PI0";
				allwinner,pname = "csi_mclk0";
				allwinner,function = "csi_mclk0";
				allwinner,muxsel = <0x02>;
				allwinner,drive = <0x02>;
				allwinner,pull = <0x00>;
				linux,phandle = <0x94>;
				phandle = <0x94>;
			};

			csi_mclk0@1 {
				allwinner,pins = "PI0";
				allwinner,pname = "csi_mclk0";
				allwinner,function = "io_disabled";
				allwinner,muxsel = <0x07>;
				allwinner,drive = <0x02>;
				allwinner,pull = <0x00>;
				linux,phandle = <0x95>;
				phandle = <0x95>;
			};

			csi_mclk1@0 {
				allwinner,pins = "PE1";
				allwinner,pname = "csi_mclk1";
				allwinner,function = "csi_mclk1";
				allwinner,muxsel = <0x02>;
				allwinner,drive = <0x00>;
				allwinner,pull = <0x00>;
				linux,phandle = <0x96>;
				phandle = <0x96>;
			};

			csi_mclk1@1 {
				allwinner,pins = "PE1";
				allwinner,pname = "csi_mclk1";
				allwinner,function = "io_disabled";
				allwinner,muxsel = <0x07>;
				allwinner,drive = <0x00>;
				allwinner,pull = <0x00>;
				linux,phandle = <0x97>;
				phandle = <0x97>;
			};

			csi1@0 {
				allwinner,pins = "PE0\0PE2\0PE3\0PE4\0PE5\0PE6\0PE7\0PE8\0PE9\0PE10\0PE11";
				allwinner,pname = "csi1_pck\0csi1_hsync\0csi1_vsync\0csi1_d0\0csi1_d1\0csi1_d2\0csi1_d3\0csi1_d4\0csi1_d5\0csi1_d6\0csi1_d7";
				allwinner,function = "csi1";
				allwinner,muxsel = <0x02>;
				allwinner,drive = <0x01>;
				allwinner,pull = <0x00>;
				linux,phandle = <0x98>;
				phandle = <0x98>;
			};

			csi1@1 {
				allwinner,pins = "PE0\0PE2\0PE3\0PE4\0PE5\0PE6\0PE7\0PE8\0PE9\0PE10\0PE11";
				allwinner,pname = "csi1_pck\0csi1_hsync\0csi1_vsync\0csi1_d0\0csi1_d1\0csi1_d2\0csi1_d3\0csi1_d4\0csi1_d5\0csi1_d6\0csi1_d7";
				allwinner,function = "io_disabled";
				allwinner,muxsel = <0x07>;
				allwinner,drive = <0x01>;
				allwinner,pull = <0x00>;
				linux,phandle = <0x99>;
				phandle = <0x99>;
			};

			scr0@0 {
				allwinner,pins = "PH21\0PH24\0PH25\0PH26\0PH27";
				allwinner,pname = "scr0_rst\0scr0_det\0scr0_vccen\0scr0_sck\0scr0_sda";
				allwinner,function = "sim0";
				allwinner,muxsel = <0x02>;
				allwinner,drive = <0x00>;
				allwinner,pull = <0x01>;
				linux,phandle = <0xe5>;
				phandle = <0xe5>;
			};

			scr0@1 {
				allwinner,pins = "PH22\0PH23";
				allwinner,pname = "scr0_vppen\0scr0_vppp";
				allwinner,function = "sim0";
				allwinner,muxsel = <0x02>;
				allwinner,drive = <0x00>;
				allwinner,pull = <0x01>;
				linux,phandle = <0xe6>;
				phandle = <0xe6>;
			};

			scr0@2 {
				allwinner,pins = "PH21\0PH22\0PH23\0PH24\0PH25\0PH26\0P27";
				allwinner,function = "io_disabled";
				allwinner,muxsel = <0x07>;
				allwinner,drive = <0x00>;
				allwinner,pull = <0x00>;
				linux,phandle = <0xe7>;
				phandle = <0xe7>;
			};

			scr1@0 {
				allwinner,pins = "PD15\0PD16\0PD12\0PD13\0PD14";
				allwinner,pname = "scr1_rst\0scr1_det\0scr1_vccen\0scr1_sck\0scr1_sda";
				allwinner,function = "sim1";
				allwinner,muxsel = <0x04>;
				allwinner,drive = <0x01>;
				allwinner,pull = <0x01>;
				linux,phandle = <0xe8>;
				phandle = <0xe8>;
			};

			scr1@1 {
				allwinner,pins = "PE14\0PE15";
				allwinner,pname = "scr1_vppen\0scr1_vppp";
				allwinner,function = "sim1";
				allwinner,muxsel = <0x03>;
				allwinner,drive = <0x01>;
				allwinner,pull = <0x01>;
				linux,phandle = <0xe9>;
				phandle = <0xe9>;
			};

			scr1@2 {
				allwinner,pins = "PD15\0PD16\0PD12\0PD13\0PD14\0PE14\0PE15";
				allwinner,function = "io_disabled";
				allwinner,muxsel = <0x07>;
				allwinner,drive = <0x01>;
				allwinner,pull = <0x00>;
				linux,phandle = <0xea>;
				phandle = <0xea>;
			};

			nand0@0 {
				allwinner,pins = "PC0\0PC1\0PC2\0PC4\0PC6\0PC7\0PC8\0PC9\0PC10\0PC11\0PC12\0PC13\0PC14";
				allwinner,pname = "nand0_we\0nand0_ale\0nand0_cle\0nand0_nre\0nand0_d7\0nand0_d6\0nand0_d5\0nand0_d4\0nand0_ndqs\0nand0_d3\0nand0_d2\0nand0_d1\0nand0_d0";
				allwinner,function = "nand0";
				allwinner,muxsel = <0x02>;
				allwinner,drive = <0x01>;
				allwinner,pull = <0x00>;
				linux,phandle = <0xeb>;
				phandle = <0xeb>;
			};

			nand0@1 {
				allwinner,pins = "PC3\0PC5";
				allwinner,pname = "nand0_ce0\0nand0_rb0";
				allwinner,function = "nand0";
				allwinner,muxsel = <0x02>;
				allwinner,drive = <0x01>;
				allwinner,pull = <0x01>;
				linux,phandle = <0xec>;
				phandle = <0xec>;
			};

			nand0@2 {
				allwinner,pins = "PC0\0PC1\0PC2\0PC3\0PC4\0PC5\0PC6\0PC7\0PC8\0PC9\0PC10\0PC11\0PC12\0PC13\0PC14";
				allwinner,function = "io_disabled";
				allwinner,muxsel = <0x07>;
				allwinner,drive = <0x01>;
				allwinner,pull = <0x00>;
				linux,phandle = <0xed>;
				phandle = <0xed>;
			};

			hdmi@0 {
				allwinner,pins = "PH13\0PH14";
				allwinner,function = "ddc";
				allwinner,muxsel = <0x03>;
				allwinner,drive = <0x01>;
				allwinner,pull = <0x00>;
				linux,phandle = <0xee>;
				phandle = <0xee>;
			};

			hdmi@1 {
				allwinner,pins = "PH13\0PH14";
				allwinner,function = "io_disabled";
				allwinner,muxsel = <0x07>;
				allwinner,drive = <0x01>;
				allwinner,pull = <0x00>;
				linux,phandle = <0xef>;
				phandle = <0xef>;
			};

			hdmi@2 {
				allwinner,pins = "PH15";
				allwinner,function = "hcec";
				allwinner,muxsel = <0x03>;
				allwinner,drive = <0x01>;
				allwinner,pull = <0x00>;
				linux,phandle = <0xf0>;
				phandle = <0xf0>;
			};

			hdmi@3 {
				allwinner,pins = "PH15";
				allwinner,function = "io_disabled";
				allwinner,muxsel = <0x07>;
				allwinner,drive = <0x01>;
				allwinner,pull = <0x00>;
				linux,phandle = <0xf1>;
				phandle = <0xf1>;
			};

			gmac@0 {
				allwinner,pins = "PD1\0PD2\0PD3\0PD4\0PD5\0PD6\0PD7\0PD8\0PD18\0PD20\0PD21";
				allwinner,function = "gmac0";
				allwinner,muxsel = <0x05>;
				allwinner,drive = <0x01>;
				allwinner,pull = <0x00>;
				linux,phandle = <0xa8>;
				phandle = <0xa8>;
			};

			gmac@1 {
				allwinner,pins = "PD1\0PD2\0PD3\0PD4\0PD5\0PD6\0PD7\0PD8\0PD18\0PD20\0PD21";
				allwinner,function = "io_disabled";
				allwinner,muxsel = <0x07>;
				allwinner,drive = <0x01>;
				allwinner,pull = <0x00>;
				linux,phandle = <0xa9>;
				phandle = <0xa9>;
			};

			card0_boot_para@0 {
				linux,phandle = <0x13c>;
				phandle = <0x13c>;
				allwinner,pins = "PF0\0PF1\0PF2\0PF3\0PF4\0PF5";
				allwinner,function = "card0_boot_para";
				allwinner,pname = "sdc_d1\0sdc_d0\0sdc_clk\0sdc_cmd\0sdc_d3\0sdc_d2";
				allwinner,muxsel = <0x02>;
				allwinner,pull = <0x01>;
				allwinner,drive = <0xffffffff>;
				allwinner,data = <0xffffffff>;
			};

			card2_boot_para@0 {
				linux,phandle = <0x13d>;
				phandle = <0x13d>;
				allwinner,pins = "PC2\0PC3\0PC6\0PC8\0PC10\0PC4\0PC5\0PC7\0PC9\0PC11\0PC1\0PC0";
				allwinner,function = "card2_boot_para";
				allwinner,pname = "sdc_clk\0sdc_cmd\0sdc_d0\0sdc_d1\0sdc_d2\0sdc_d3\0sdc_d4\0sdc_d5\0sdc_d6\0sdc_d7\0sdc_emmc_rst\0sdc_ds";
				allwinner,muxsel = <0x03>;
				allwinner,pull = <0x01>;
				allwinner,drive = <0x03>;
				allwinner,data = <0xffffffff>;
			};

			twi_para@0 {
				linux,phandle = <0x13e>;
				phandle = <0x13e>;
				allwinner,pins = "PH14\0PH15";
				allwinner,function = "twi_para";
				allwinner,pname = "twi_scl\0twi_sda";
				allwinner,muxsel = <0x02>;
				allwinner,pull = <0xffffffff>;
				allwinner,drive = <0xffffffff>;
				allwinner,data = <0xffffffff>;
			};

			uart_para@0 {
				linux,phandle = <0x13f>;
				phandle = <0x13f>;
				allwinner,pins = "PH9\0PH10";
				allwinner,function = "uart_para";
				allwinner,pname = "uart_debug_tx\0uart_debug_rx";
				allwinner,muxsel = <0x05>;
				allwinner,pull = <0x01>;
				allwinner,drive = <0xffffffff>;
				allwinner,data = <0xffffffff>;
			};

			uart2@0 {
				linux,phandle = <0x140>;
				phandle = <0x140>;
				allwinner,pins = "PH5\0PH6\0PH7\0PH8";
				allwinner,function = "uart2";
				allwinner,pname = "uart2_tx\0uart2_rx\0uart2_rts\0uart2_cts";
				allwinner,muxsel = <0x05>;
				allwinner,pull = <0x01>;
				allwinner,drive = <0xffffffff>;
				allwinner,data = <0xffffffff>;
			};

			uart2@1 {
				linux,phandle = <0x141>;
				phandle = <0x141>;
				allwinner,pins = "PH5\0PH6\0PH7\0PH8";
				allwinner,function = "uart2";
				allwinner,pname = "uart2_tx\0uart2_rx\0uart2_rts\0uart2_cts";
				allwinner,muxsel = <0x07>;
				allwinner,pull = <0x01>;
				allwinner,drive = <0xffffffff>;
				allwinner,data = <0xffffffff>;
			};

			jtag_para@0 {
				linux,phandle = <0x142>;
				phandle = <0x142>;
				allwinner,pins = "PH9\0PH10\0PH11\0PH12";
				allwinner,function = "jtag_para";
				allwinner,pname = "jtag_ms\0jtag_ck\0jtag_do\0jtag_di";
				allwinner,muxsel = <0x03>;
				allwinner,pull = <0xffffffff>;
				allwinner,drive = <0xffffffff>;
				allwinner,data = <0xffffffff>;
			};
		};

		dma-controller@03002000 {
			compatible = "allwinner,sun8i-dma";
			reg = <0x00 0x3002000 0x00 0x1000>;
			interrupts = <0x00 0x0a 0x04>;
			clocks = <0x13>;
			#dma-cells = <0x01>;
			linux,phandle = <0xf2>;
			phandle = <0xf2>;
		};

		timer@03009000 {
			compatible = "allwinner,sun4i-a10-timer";
			device_type = "soc_timer";
			reg = <0x00 0x3009000 0x00 0x90>;
			interrupts = <0x00 0x3c 0x04>;
			clocks = <0x08 0x12>;
			linux,phandle = <0xf3>;
			phandle = <0xf3>;
		};

		rtc@07000000 {
			compatible = "allwinner,sun8i-rtc\0allwinner,sunxi-rtc";
			device_type = "rtc";
			reg = <0x00 0x7000000 0x00 0x400>;
			interrupts = <0x00 0x69 0x04>;
			auto_switch;
			wakeup-source;
			gpr_offset = <0x100>;
			gpr_len = <0x08>;
			linux,phandle = <0xf4>;
			phandle = <0xf4>;
		};

		watchdog@030090a0 {
			compatible = "allwinner,sun50i-wdt";
			reg = <0x00 0x30090a0 0x00 0x20>;
			interrupts = <0x00 0x0e 0x04>;
			linux,phandle = <0xf5>;
			phandle = <0xf5>;
		};

		ve@01c0e000 {
			compatible = "allwinner,sunxi-cedar-ve";
			reg = <0x00 0x1c0e000 0x00 0x1000 0x00 0x3000000 0x00 0x10 0x00 0x3001000 0x00 0x800 0x00 0x7010000 0x00 0x300>;
			interrupts = <0x00 0x19 0x04>;
			clocks = <0x14 0x0c>;
			iommus = <0x15 0x03 0x01>;
		};

		ise@01c10000 {
			compatible = "allwinner,sunxi-ise";
			reg = <0x00 0x1c10000 0x00 0x1000 0x00 0x3001000 0x00 0x800>;
			interrupts = <0x00 0x18 0x04>;
			linux,phandle = <0xf6>;
			phandle = <0xf6>;
		};

		eise@0x02300000 {
			compatible = "allwinner,sunxi-eise";
			reg = <0x00 0x2300000 0x00 0x1000 0x00 0x3001000 0x00 0x800>;
			interrupts = <0x00 0x1a 0x04>;
			clocks = <0x14 0x16>;
			iommus = <0x15 0x01 0x01>;
			linux,phandle = <0xf7>;
			phandle = <0xf7>;
		};

		uart@05000000 {
			compatible = "allwinner,sun8i-uart";
			device_type = "uart0";
			reg = <0x00 0x5000000 0x00 0x400>;
			interrupts = <0x00 0x31 0x04>;
			clocks = <0x17>;
			pinctrl-names = "default\0sleep";
			pinctrl-0 = <0x18>;
			pinctrl-1 = <0x19>;
			uart0_port = <0x00>;
			uart0_type = <0x02>;
			status = "okay";
			linux,phandle = <0xf8>;
			phandle = <0xf8>;
		};

		uart@05000400 {
			compatible = "allwinner,sun8i-uart";
			device_type = "uart1";
			reg = <0x00 0x5000400 0x00 0x400>;
			interrupts = <0x00 0x32 0x04>;
			clocks = <0x1a>;
			pinctrl-names = "default\0sleep";
			pinctrl-0 = <0x1b>;
			pinctrl-1 = <0x1c>;
			uart1_port = <0x01>;
			uart1_type = <0x04>;
			status = "disabled";
			linux,phandle = <0xb3>;
			phandle = <0xb3>;
		};

		uart@05000800 {
			compatible = "allwinner,sun8i-uart";
			device_type = "uart2";
			reg = <0x00 0x5000800 0x00 0x400>;
			interrupts = <0x00 0x33 0x04>;
			clocks = <0x1d>;
			pinctrl-names = "default\0sleep";
			uart2_port = <0x02>;
			uart2_type = <0x04>;
			status = "okay";
			linux,phandle = <0xf9>;
			phandle = <0xf9>;
			pinctrl-0 = <0x140>;
			pinctrl-1 = <0x141>;
		};

		uart@05000c00 {
			compatible = "allwinner,sun8i-uart";
			device_type = "uart3";
			reg = <0x00 0x5000c00 0x00 0x400>;
			interrupts = <0x00 0x34 0x04>;
			clocks = <0x20>;
			pinctrl-names = "default\0sleep";
			pinctrl-0 = <0x21>;
			pinctrl-1 = <0x22>;
			uart3_port = <0x03>;
			uart3_type = <0x04>;
			status = "disabled";
			linux,phandle = <0xfa>;
			phandle = <0xfa>;
		};

		s_owc@07040400 {
			compatible = "allwinner,sunxi-owc";
			device_type = "s_owc0";
			reg = <0x00 0x7040400 0x00 0x30>;
			interrupts = <0x00 0x72 0x04>;
			clocks = <0x08 0x23>;
			pinctrl-names = "default\0sleep";
			pinctrl-0 = <0x24>;
			pinctrl-1 = <0x25>;
			status = "okay";
			linux,phandle = <0xfb>;
			phandle = <0xfb>;
		};

		twi@0x05002000 {
			#address-cells = <0x01>;
			#size-cells = <0x00>;
			compatible = "allwinner,sun8i-twi";
			device_type = "twi0";
			reg = <0x00 0x5002000 0x00 0x400>;
			interrupts = <0x00 0x29 0x04>;
			clocks = <0x26>;
			clock-frequency = <0x61a80>;
			pinctrl-names = "default\0sleep";
			pinctrl-0 = <0x27>;
			pinctrl-1 = <0x28>;
			twi_drv_used = <0x00>;
			status = "okay";
			linux,phandle = <0xb5>;
			phandle = <0xb5>;

			da380 {
				status = "okay";
				compatible = "da380";
				reg = <0x27>;
			};

			es7243e {
				status = "okay";
				compatible = "ES7243E_MicArray_0";
				reg = <0x12>;
			};

			es8388 {
				status = "disabled";
				compatible = "es8388";
				reg = <0x10>;
			};
		};

		twi@0x05002400 {
			#address-cells = <0x01>;
			#size-cells = <0x00>;
			compatible = "allwinner,sun8i-twi";
			device_type = "twi1";
			reg = <0x00 0x5002400 0x00 0x400>;
			interrupts = <0x00 0x2a 0x04>;
			clocks = <0x29>;
			clock-frequency = <0x30d40>;
			pinctrl-names = "default\0sleep";
			pinctrl-0 = <0x2a>;
			pinctrl-1 = <0x2b>;
			twi_drv_used = <0x00>;
			status = "okay";
			linux,phandle = <0xfc>;
			phandle = <0xfc>;
		};

		twi@0x05002800 {
			#address-cells = <0x01>;
			#size-cells = <0x00>;
			compatible = "allwinner,sun8i-twi";
			device_type = "twi2";
			reg = <0x00 0x5002800 0x00 0x400>;
			interrupts = <0x00 0x2b 0x04>;
			clocks = <0x2c>;
			clock-frequency = <0x30d40>;
			pinctrl-names = "default\0sleep";
			pinctrl-0 = <0x2d>;
			pinctrl-1 = <0x2e>;
			twi_drv_used = <0x00>;
			status = "okay";
			linux,phandle = <0xfd>;
			phandle = <0xfd>;

			pcf8563 {
				status = "okay";
				compatible = "pcf8563";
				reg = <0x51>;
			};
		};

		twi@0x05002c00 {
			#address-cells = <0x01>;
			#size-cells = <0x00>;
			compatible = "allwinner,sun8i-twi";
			device_type = "twi3";
			reg = <0x00 0x5002c00 0x00 0x400>;
			interrupts = <0x00 0x2c 0x04>;
			clocks = <0x2f>;
			clock-frequency = <0x30d40>;
			pinctrl-names = "default\0sleep";
			pinctrl-0 = <0x30>;
			pinctrl-1 = <0x31>;
			twi_drv_used = <0x00>;
			status = "okay";
			linux,phandle = <0xfe>;
			phandle = <0xfe>;

			qn8027 {
				status = "okay";
				compatible = "qn8027";
				reg = <0x2c>;
			};
		};

		twi@0x07081400 {
			#address-cells = <0x01>;
			#size-cells = <0x00>;
			compatible = "allwinner,sun8i-twi";
			device_type = "twi4";
			reg = <0x00 0x7081400 0x00 0x400>;
			interrupts = <0x00 0x6b 0x04>;
			clocks = <0x32>;
			clock-frequency = <0x30d40>;
			pinctrl-names = "default\0sleep";
			pinctrl-0 = <0x33>;
			pinctrl-1 = <0x34>;
			status = "okay";
			no_suspend = <0x01>;
			twi_drv_used = <0x01>;
			linux,phandle = <0xff>;
			phandle = <0xff>;

			pmu@0 {
				compatible = "x-powers,axp152";
				reg = <0x30>;
				#address-cells = <0x01>;
				#size-cells = <0x00>;
				interrupts = <0x00 0x08>;
				interrupt-parent = <0x35>;
				status = "okay";
				wakeup-source;
				pwr_hold-gpios = <0x36 0x04 0x15 0x01 0x00 0x03 0x00>;
				linux,phandle = <0x100>;
				phandle = <0x100>;

				vbus {
					compatible = "x-powers,axp152-vbus";
					acin-gpios = <0x36 0x03 0x00 0x00 0x00 0x03 0x00>;
				};

				powerkey@0 {
					status = "okay";
					compatible = "x-powers,axp152-pek";
					pmu_powkey_on_time = <0x80>;
					pmu_powkey_long_time = <0x3e8>;
					pmu_powkey_off_en = <0x01>;
					pmu_pwrok_time = <0x40>;
					pmu_powkey_off_time = <0x1770>;
					wakeup_rising;
					autorepeat;
					linux,phandle = <0x101>;
					phandle = <0x101>;

					Power {
						label = "Power Key";
						linux,code = <0x74>;
						gpios = <0x36 0x04 0x0e 0x00 0x00 0x03 0x01>;
						debounce-interval = <0x05>;
					};
				};

				regulators@0 {
					linux,phandle = <0x102>;
					phandle = <0x102>;

					dcdc1 {
						regulator-name = "axp152-dcdc1";
						regulator-min-microvolt = <0x325aa0>;
						regulator-max-microvolt = <0x325aa0>;
						regulator-always-on;
						linux,phandle = <0x37>;
						phandle = <0x37>;
					};

					dcdc2 {
						regulator-name = "axp152-dcdc2";
						regulator-min-microvolt = <0xdbba0>;
						regulator-max-microvolt = <0xdbba0>;
						regulator-always-on;
						linux,phandle = <0x38>;
						phandle = <0x38>;
					};

					dcdc3 {
						regulator-name = "axp152-dcdc3";
						regulator-min-microvolt = <0x16e360>;
						regulator-max-microvolt = <0x16e360>;
						regulator-always-on;
						linux,phandle = <0x39>;
						phandle = <0x39>;
					};

					dcdc4 {
						regulator-name = "axp152-dcdc4";
						regulator-min-microvolt = <0x124f80>;
						regulator-max-microvolt = <0x124f80>;
						regulator-always-on;
						linux,phandle = <0x3a>;
						phandle = <0x3a>;
					};

					aldo1 {
						regulator-name = "axp152-aldo1";
						regulator-min-microvolt = <0x1b7740>;
						regulator-max-microvolt = <0x1b7740>;
						regulator-always-on;
						linux,phandle = <0x3b>;
						phandle = <0x3b>;
					};

					aldo2 {
						regulator-name = "axp152-aldo2";
						regulator-min-microvolt = <0x2ab980>;
						regulator-max-microvolt = <0x325aa0>;
						regulator-always-on;
						linux,phandle = <0x3c>;
						phandle = <0x3c>;
					};

					dldo1 {
						regulator-name = "axp152-dldo1";
						regulator-min-microvolt = <0x325aa0>;
						regulator-max-microvolt = <0x325aa0>;
						regulator-always-on;
						linux,phandle = <0x3d>;
						phandle = <0x3d>;
					};

					dldo2 {
						regulator-name = "axp152-dldo2";
						regulator-min-microvolt = <0x325aa0>;
						regulator-max-microvolt = <0x325aa0>;
						regulator-always-on;
						linux,phandle = <0x3e>;
						phandle = <0x3e>;
					};

					ldo0 {
						regulator-name = "axp152-ldo0";
						regulator-min-microvolt = <0x3d090>;
						regulator-max-microvolt = <0x4c4b40>;
						regulator-always-on;
						linux,phandle = <0x3f>;
						phandle = <0x3f>;
					};
				};

				virtual-dcdc1 {
					compatible = "xpower-vregulator,dcdc1";
					dcdc1-supply = <0x37>;
				};

				virtual-dcdc2 {
					compatible = "xpower-vregulator,dcdc2";
					dcdc2-supply = <0x38>;
				};

				virtual-dcdc3 {
					compatible = "xpower-vregulator,dcdc3";
					dcdc3-supply = <0x39>;
				};

				virtual-dcdc4 {
					compatible = "xpower-vregulator,dcdc4";
					dcdc4-supply = <0x3a>;
				};

				virtual-aldo1 {
					compatible = "xpower-vregulator,aldo1";
					aldo1-supply = <0x3b>;
				};

				virtual-aldo2 {
					compatible = "xpower-vregulator,aldo2";
					aldo2-supply = <0x3c>;
				};

				virtual-dldo1 {
					compatible = "xpower-vregulator,dldo1";
					dldo1-supply = <0x3d>;
				};

				virtual-dldo2 {
					compatible = "xpower-vregulator,dldo2";
					dldo2-supply = <0x3e>;
				};

				virtual-ldo0 {
					compatible = "xpower-vregulator,ldo0";
					ldo0-supply = <0x3f>;
				};

				axp_gpio@0 {
					gpio-controller;
					#size-cells = <0x00>;
					#gpio-cells = <0x06>;
					status = "okay";
					linux,phandle = <0x103>;
					phandle = <0x103>;
				};
			};
		};

		usbc0@0 {
			device_type = "usbc0";
			compatible = "allwinner,sunxi-otg-manager";
			usb_port_type = <0x01>;
			usb_detect_type = <0x00>;
			usb_id_gpio;
			usb_det_vbus_gpio;
			usb_drv_vbus_gpio;
			usb_host_init_state = <0x00>;
			usb_regulator_io = "nocare";
			usb_wakeup_suspend = <0x00>;
			usb_luns = <0x03>;
			usb_serial_unique = <0x00>;
			usb_serial_number = "20080411";
			rndis_wceis = <0x01>;
			status = "okay";
			usb_detect_mode = <0x00>;
			linux,phandle = <0x104>;
			phandle = <0x104>;
		};

		udc-controller@0x05100000 {
			compatible = "allwinner,sunxi-udc";
			reg = <0x00 0x5100000 0x00 0x1000 0x00 0x00 0x00 0x100>;
			interrupts = <0x00 0x40 0x04>;
			clocks = <0x40 0x41>;
			status = "okay";
			linux,phandle = <0x105>;
			phandle = <0x105>;
		};

		ehci0-controller@0x05101000 {
			compatible = "allwinner,sunxi-ehci0";
			reg = <0x00 0x5101000 0x00 0xfff 0x00 0x00 0x00 0x100 0x00 0x5100000 0x00 0x1000>;
			interrupts = <0x00 0x41 0x04>;
			clocks = <0x40 0x42>;
			hci_ctrl_no = <0x00>;
			status = "okay";
			linux,phandle = <0x106>;
			phandle = <0x106>;
		};

		ohci0-controller@0x05101400 {
			compatible = "allwinner,sunxi-ohci0";
			reg = <0x00 0x5101000 0x00 0xfff 0x00 0x00 0x00 0x100 0x00 0x5100000 0x00 0x1000>;
			interrupts = <0x00 0x42 0x04>;
			clocks = <0x40 0x43 0x44 0x45 0x08 0x12>;
			hci_ctrl_no = <0x00>;
			status = "okay";
			linux,phandle = <0x107>;
			phandle = <0x107>;
		};

		daudio@0x05090000 {
			compatible = "allwinner,sunxi-daudio";
			reg = <0x00 0x5090000 0x00 0x7c>;
			clocks = <0x03 0x46>;
			pinctrl-names = "default\0sleep";
			pinctrl-0 = <0x47>;
			pinctrl-1 = <0x48>;
			device_type = "daudio0";
			tdm_num = <0x00>;
			status = "okay";
			rate_max = <0x2ee00>;
			channels_max = <0x08>;
			buffer_bytes_max = <0x20000>;
			period_bytes_max = <0x10000>;
			periods_max = <0x08>;
			fifo_size = <0x80>;
			mclk_div = <0x10>;
			frametype = <0x00>;
			tdm_config = <0x00>;
			sign_extend = <0x00>;
			tx_data_mode = <0x00>;
			rx_data_mode = <0x00>;
			msb_lsb_first = <0x00>;
			pcm_lrck_period = <0x40>;
			slot_width_select = <0x10>;
			linux,phandle = <0x4e>;
			phandle = <0x4e>;
		};

		daudio@0x05091000 {
			compatible = "allwinner,sunxi-daudio";
			reg = <0x00 0x5091000 0x00 0x7c>;
			clocks = <0x03 0x49>;
			pinctrl-names = "default\0sleep";
			pinctrl-0 = <0x4a>;
			pinctrl-1 = <0x4b>;
			device_type = "daudio1";
			tdm_num = <0x01>;
			status = "okay";
			rate_max = <0x2ee00>;
			channels_max = <0x08>;
			buffer_bytes_max = <0x20000>;
			period_bytes_max = <0x10000>;
			periods_max = <0x08>;
			fifo_size = <0x80>;
			pcm_lrck_period = <0x20>;
			pcm_lrckr_period = <0x01>;
			slot_width_select = <0x20>;
			pcm_lsb_first = <0x00>;
			tx_data_mode = <0x00>;
			rx_data_mode = <0x00>;
			frametype = <0x00>;
			tdm_config = <0x01>;
			mclk_div = <0x00>;
			linux,phandle = <0x4f>;
			phandle = <0x4f>;
		};

		codec@0x05096000 {
			compatible = "allwinner,sunxi-internal-codec";
			reg = <0x00 0x5096000 0x00 0x320>;
			clocks = <0x03 0x4c>;
			device_type = "codec";
			status = "okay";
			rate_max = <0x2ee00>;
			channels_max = <0x08>;
			buffer_bytes_max = <0x20000>;
			period_bytes_max = <0x10000>;
			periods_max = <0x08>;
			fifo_size = <0x80>;
			pa_level = <0x01>;
			main_gain = <0x18>;
			adcdrc_cfg = <0x00>;
			adchpf_cfg = <0x00>;
			dacdrc_cfg = <0x00>;
			dachpf_cfg = <0x00>;
			digital_vol = <0x00>;
			lineout_vol = <0x1a>;
			pa_msleep_time = <0xa0>;
			gpio-spk = <0x36 0x0b 0x00 0x01 0x01 0x01 0x01>;
			linux,phandle = <0x4d>;
			phandle = <0x4d>;
		};

		sound@0 {
			compatible = "allwinner,sunxi-codec-machine";
			interrupts = <0x00 0x1c 0x04>;
			sunxi,audio-codec = <0x4d>;
			device_type = "sndcodec";
			status = "okay";
			linux,phandle = <0x108>;
			phandle = <0x108>;
		};

		sound@1 {
			compatible = "allwinner,sunxi-daudio0-machine";
			sunxi,daudio-controller = <0x4e>;
			device_type = "snddaudio0";
			status = "okay";
			audio_format = <0x04>;
			daudio_master = <0x04>;
			signal_inversion = <0x03>;
			linux,phandle = <0x109>;
			phandle = <0x109>;
		};

		sound@2 {
			compatible = "allwinner,sunxi-daudio1-machine";
			sunxi,daudio-controller = <0x4f>;
			device_type = "snddaudio1";
			status = "okay";
			daudio_master = <0x04>;
			audio_format = <0x01>;
			signal_inversion = <0x01>;
			sunxi,snddaudio-codec = "es7243e.0-0012";
			sunxi,snddaudio-codec-dai = "ES7243E HiFi 0";
			linux,phandle = <0x10a>;
			phandle = <0x10a>;
		};

		spi@05010000 {
			#address-cells = <0x01>;
			#size-cells = <0x00>;
			compatible = "allwinner,sun8i-spi";
			device_type = "spi0";
			reg = <0x00 0x5010000 0x00 0x1000>;
			interrupts = <0x00 0x36 0x04>;
			clocks = <0x05 0x50>;
			clock-frequency = <0x11e1a300>;
			pinctrl-names = "default\0sleep";
			pinctrl-0 = <0x51 0x52>;
			pinctrl-1 = <0x53>;
			spi0_cs_number = <0x02>;
			spi0_cs_bitmap = <0x03>;
			status = "okay";
			linux,phandle = <0x10b>;
			phandle = <0x10b>;

			spi_board0 {
				device_type = "spi_board0";
				compatible = "m25p80";
				spi-max-frequency = <0x2faf080>;
				reg = <0x00>;
				spi-rx-bus-width = <0x04>;
				spi-tx-bus-width = <0x04>;
			};
		};

		spi@05011000 {
			#address-cells = <0x01>;
			#size-cells = <0x00>;
			compatible = "allwinner,sun8i-spi";
			device_type = "spi1";
			reg = <0x00 0x5011000 0x00 0x1000>;
			interrupts = <0x00 0x37 0x04>;
			clocks = <0x05 0x54>;
			clock-frequency = <0xbebc200>;
			pinctrl-names = "default\0sleep";
			pinctrl-0 = <0x55 0x56>;
			pinctrl-1 = <0x57>;
			spi1_cs_number = <0x02>;
			spi1_cs_bitmap = <0x03>;
			status = "disabled";
			spi_slave_mode = <0x00>;
			linux,phandle = <0x10c>;
			phandle = <0x10c>;

			spi_board1 {
				device_type = "spi_board1";
				compatible = "rohm,dh2228fv";
				spi-max-frequency = <0x5f5e100>;
				reg = <0x00>;
				spi-rx-bus-width = <0x01>;
				spi-tx-bus-width = <0x01>;
			};
		};

		spi@05012000 {
			#address-cells = <0x01>;
			#size-cells = <0x00>;
			compatible = "allwinner,sun8i-spi";
			device_type = "spi2";
			reg = <0x00 0x5012000 0x00 0x1000>;
			interrupts = <0x00 0x38 0x04>;
			clocks = <0x05 0x58>;
			clock-frequency = <0xbebc200>;
			pinctrl-names = "default\0sleep";
			pinctrl-0 = <0x59 0x5a>;
			pinctrl-1 = <0x5b>;
			spi2_cs_number = <0x01>;
			spi2_cs_bitmap = <0x01>;
			status = "disabled";
			spi_slave_mode = <0x00>;
			linux,phandle = <0x10d>;
			phandle = <0x10d>;

			spi_board2 {
				device_type = "spi_board2";
				compatible = "rohm,dh2228fv";
				spi-max-frequency = <0x5f5e100>;
				reg = <0x00>;
				spi-rx-bus-width = <0x01>;
				spi-tx-bus-width = <0x01>;
			};
		};

		sdmmc@04022000 {
			compatible = "allwinner,sunxi-mmc-v4p5x";
			device_type = "sdc2";
			reg = <0x00 0x4022000 0x00 0x1000>;
			interrupts = <0x00 0x30 0x04>;
			clocks = <0x08 0x14 0x5c 0x5d 0x5e>;
			clock-names = "osc24m\0pll_periph\0mmc\0ahb\0rst";
			pinctrl-names = "default\0sleep";
			pinctrl-0 = <0x5f 0x60>;
			pinctrl-1 = <0x61>;
			bus-width = <0x08>;
			cap-sd-highspeed;
			cap-mmc-highspeed;
			cap-wait-while-busy;
			mmc-high-capacity-erase-size;
			cap-erase;
			max-frequency = <0x2faf080>;
			sdc_tm4_sm0_freq0 = <0x00>;
			sdc_tm4_sm0_freq1 = <0x00>;
			sdc_tm4_sm1_freq0 = <0x00>;
			sdc_tm4_sm1_freq1 = <0x00>;
			sdc_tm4_sm2_freq0 = <0x00>;
			sdc_tm4_sm2_freq1 = <0x00>;
			sdc_tm4_sm3_freq0 = <0x5000000>;
			sdc_tm4_sm3_freq1 = <0x05>;
			sdc_tm4_sm4_freq0 = <0x50000>;
			sdc_tm4_sm4_freq1 = <0x04>;
			status = "disabled";
			non-removable;
			no-sdio;
			no-sd;
			sunxi-power-save-mode;
			sunxi-dis-signal-vol-sw;
			linux,phandle = <0x10e>;
			phandle = <0x10e>;
		};

		sdmmc@04020000 {
			compatible = "allwinner,sunxi-mmc-v4p1x";
			device_type = "sdc0";
			reg = <0x00 0x4020000 0x00 0x1000>;
			interrupts = <0x00 0x2e 0x04>;
			clocks = <0x08 0x14 0x62 0x63 0x64>;
			clock-names = "osc24m\0pll_periph\0mmc\0ahb\0rst";
			pinctrl-names = "default\0sleep\0uart_jtag";
			pinctrl-0 = <0x65>;
			pinctrl-1 = <0x66>;
			pinctrl-2 = <0x67>;
			max-frequency = <0x2faf080>;
			bus-width = <0x04>;
			cap-sd-highspeed;
			cap-mmc-highspeed;
			cap-wait-while-busy;
			status = "okay";
			cd-gpios = <0x36 0x05 0x06 0x00 0x01 0x03 0xffffffff>;
			sunxi-power-save-mode;
			sd-uhs-sdr50;
			sd-uhs-sdr104;
			no-sdio;
			broken-cd;
			ctl-spec-caps = <0x08>;
			vmmc-supply = <0x37>;
			vqmmc33sw-supply = <0x37>;
			vdmmc33sw-supply = <0x37>;
			vqmmc18sw-supply = <0x37>;
			vdmmc18sw-supply = <0x37>;
			filter_speed = <0x300000>;
			filter_sector = <0x08>;
			perf_enable = <0x00>;
			linux,phandle = <0x10f>;
			phandle = <0x10f>;
		};

		sdmmc@04021000 {
			compatible = "allwinner,sunxi-mmc-v4p1x";
			device_type = "sdc1";
			reg = <0x00 0x4021000 0x00 0x1000>;
			interrupts = <0x00 0x2f 0x04>;
			clocks = <0x08 0x14 0x68 0x69 0x6a>;
			clock-names = "osc24m\0pll_periph\0mmc\0ahb\0rst";
			pinctrl-names = "default\0sleep";
			pinctrl-0 = <0x6b>;
			pinctrl-1 = <0x6c>;
			max-frequency = <0x2faf080>;
			bus-width = <0x04>;
			cap-sd-highspeed;
			cap-mmc-highspeed;
			cap-wait-while-busy;
			sunxi-dly-52M-ddr4 = <0x01 0x00 0x00 0x00 0x02>;
			sunxi-dly-104M = <0x01 0x00 0x00 0x00 0x01>;
			sunxi-dly-208M = <0x01 0x00 0x00 0x00 0x01>;
			status = "okay";
			cap-sdio-irq;
			keep-power-in-suspend;
			ignore-pm-notify;
			linux,phandle = <0x110>;
			phandle = <0x110>;
		};

		disp@01000000 {
			compatible = "allwinner,sunxi-disp";
			reg = <0x00 0x1000000 0x00 0x3fffff 0x00 0x6510000 0x00 0xfff 0x00 0x6511000 0x00 0xfff 0x00 0x6504000 0x00 0x2000>;
			interrupts = <0x00 0x3e 0x04 0x00 0x3f 0x04 0x00 0x2d 0x04>;
			clocks = <0x0a 0x6d 0x6e 0x6f 0x0f>;
			boot_disp = <0x00>;
			fb_base = <0x00>;
			iommus = <0x15 0x00 0x00>;
			status = "okay";
			disp_init_enable = <0x01>;
			disp_mode = <0x00>;
			screen0_output_type = <0x01>;
			screen0_output_mode = <0x04>;
			dev0_output_type = <0x01>;
			dev0_output_mode = <0x04>;
			dev0_screen_id = <0x00>;
			dev0_do_hpd = <0x00>;
			disp_rotation_used = <0x01>;
			degree0 = <0x01>;
			fb0_buffer_num = <0x01>;
			fb0_format = <0x00>;
			fb0_width = <0x640>;
			fb0_height = <0x258>;
			lcd0_backlight = <0x7d>;
			lcd0_bright = <0x32>;
			lcd0_contrast = <0x32>;
			lcd0_saturation = <0x39>;
			lcd0_hue = <0x32>;
			dcdc1-supply = <0x37>;
			aldo1-supply = <0x3b>;
			linux,phandle = <0x111>;
			phandle = <0x111>;
		};

		lcd0@01c0c000 {
			compatible = "allwinner,sunxi-lcd0";
			pinctrl-names = "active\0sleep";
			status = "okay";
			lcd_used = <0x01>;
			lcd_driver_name = "default_mipi";
			lcd_backlight = <0xff>;
			lcd_if = <0x04>;
			lcd_x = <0x258>;
			lcd_y = <0x640>;
			lcd_width = <0x24>;
			lcd_height = <0x2d>;
			lcd_dclk_freq = <0x39>;
			lcd_pwm_used = <0x01>;
			lcd_pwm_ch = <0x09>;
			lcd_pwm_freq = <0x5dc0>;
			lcd_pwm_pol = <0x01>;
			lcd_pwm_max_limit = <0xff>;
			lcd_hbp = <0x1e>;
			lcd_ht = <0x294>;
			lcd_hspw = <0x0c>;
			lcd_vbp = <0x18>;
			lcd_vt = <0x668>;
			lcd_vspw = <0x0c>;
			lcd_dsi_if = <0x00>;
			lcd_dsi_lane = <0x04>;
			lcd_dsi_format = <0x00>;
			lcd_dsi_te = <0x00>;
			lcd_dsi_eotp = <0x00>;
			lcd_frm = <0x00>;
			lcd_io_phase = <0x00>;
			lcd_hv_clk_phase = <0x00>;
			lcd_hv_sync_polarity = <0x00>;
			lcd_gamma_en = <0x00>;
			lcd_bright_curve_en = <0x00>;
			lcd_cmap_en = <0x00>;
			lcdgamma4iep = <0x16>;
			lcd_power = "dcdc1";
			lcd_pin_power = "aldo1";
			lcd_gpio_0 = <0x36 0x07 0x0f 0x01 0x00 0x03 0x01>;
			reset_en_delay_ms = <0x64>;
			panel_init_sequence = [00 03 f0 5a 59 00 03 f1 a5 a6 00 10 b0 98 00 00 89 77 77 77 77 46 00 00 77 00 00 0f 00 0c b1 97 c0 00 91 4f 00 00 87 00 00 5f 00 17 b3 05 00 00 13 00 1b 00 11 00 19 00 0f 00 17 00 0d 00 15 1d 22 0b 00 00 17 b4 04 00 00 12 00 1a 00 10 00 18 00 0e 00 16 00 0c 00 14 1d 22 0a 00 00 0b b2 00 91 08 8b 08 00 22 00 44 d9 00 03 b6 0e 0e 00 13 b7 01 01 09 0d 11 19 1d 15 00 25 21 00 00 00 00 02 f7 38 00 05 b8 b4 52 02 cc 00 08 bd 43 0e 0e 82 82 23 14 00 09 c1 00 10 10 04 00 3a 3a 08 00 03 c2 31 20 00 03 c3 22 30 00 09 c6 00 00 ff 00 00 ff 00 00 00 27 c8 7c 4f 3d 2f 2b 1d 23 0f 2c 2e 31 53 43 4d 40 3d 31 22 1a 7c 4f 3d 2f 2b 1d 23 0f 2c 2e 31 53 43 4d 40 3d 31 22 1a 00 04 d0 07 ff ff 00 05 d2 63 0b 08 88 00 07 d4 00 00 00 32 04 51 00 03 f1 5a 59 00 03 f0 a5 a6 c8 01 11 32 01 29];
			linux,phandle = <0x112>;
			phandle = <0x112>;
		};

		tr@01000000 {
			compatible = "allwinner,sun50i-tr";
			reg = <0x00 0x1000000 0x00 0x200bc>;
			interrupts = <0x00 0x60 0x04>;
			clocks = <0x0a>;
			status = "okay";
			linux,phandle = <0x113>;
			phandle = <0x113>;
		};

		g2d@01480000 {
			compatible = "allwinner,sunxi-g2d";
			reg = <0x00 0x1480000 0x00 0xbffff>;
			interrupts = <0x00 0x15 0x04>;
			clocks = <0x0b>;
			iommus = <0x15 0x06 0x01>;
			status = "okay";
			linux,phandle = <0x114>;
			phandle = <0x114>;
		};

		nna@02400000 {
			compatible = "allwinner,sunxi-nna";
			reg = <0x00 0x2400000 0x00 0x1ffff>;
			interrupts = <0x00 0x14 0x04>;
			clocks = <0x0d 0x70>;
			iommus = <0x15 0x02 0x01>;
			status = "okay";
			linux,phandle = <0x115>;
			phandle = <0x115>;
		};

		pwm@0300a000 {
			compatible = "allwinner,sunxi-pwm";
			reg = <0x00 0x300a000 0x00 0x400>;
			status = "okay";
			clocks = <0x71>;
			pwm-number = <0x0a>;
			pwm-base = <0x00>;
			pwms = <0x72 0x73 0x74 0x75 0x76 0x77 0x78 0x79 0x7a 0x7b>;
			linux,phandle = <0x116>;
			phandle = <0x116>;
		};

		pwm0@0300a000 {
			compatible = "allwinner,sunxi-pwm0";
			pinctrl-names = "active\0sleep";
			pinctrl-0 = <0x7c>;
			pinctrl-1 = <0x7d>;
			status = "okay";
			reg_base = <0x300a000>;
			linux,phandle = <0x72>;
			phandle = <0x72>;
		};

		pwm1@0300a000 {
			compatible = "allwinner,sunxi-pwm1";
			pinctrl-names = "active\0sleep";
			reg_base = <0x300a000>;
			pinctrl-0 = <0x7e>;
			pinctrl-1 = <0x7f>;
			status = "okay";
			linux,phandle = <0x73>;
			phandle = <0x73>;
		};

		pwm2@0300a000 {
			compatible = "allwinner,sunxi-pwm2";
			pinctrl-names = "active\0sleep";
			reg_base = <0x300a000>;
			pinctrl-0 = <0x80>;
			pinctrl-1 = <0x81>;
			status = "okay";
			linux,phandle = <0x74>;
			phandle = <0x74>;
		};

		pwm3@0300a000 {
			compatible = "allwinner,sunxi-pwm3";
			pinctrl-names = "active\0sleep";
			reg_base = <0x300a000>;
			pinctrl-0 = <0x82>;
			pinctrl-1 = <0x83>;
			status = "okay";
			linux,phandle = <0x75>;
			phandle = <0x75>;
		};

		pwm4@0300a000 {
			compatible = "allwinner,sunxi-pwm4";
			pinctrl-names = "active\0sleep";
			reg_base = <0x300a000>;
			pinctrl-0 = <0x84>;
			pinctrl-1 = <0x85>;
			status = "okay";
			linux,phandle = <0x76>;
			phandle = <0x76>;
		};

		pwm5@0300a000 {
			compatible = "allwinner,sunxi-pwm5";
			pinctrl-names = "active\0sleep";
			reg_base = <0x300a000>;
			pinctrl-0 = <0x86>;
			pinctrl-1 = <0x87>;
			status = "okay";
			linux,phandle = <0x77>;
			phandle = <0x77>;
		};

		pwm6@0300a000 {
			compatible = "allwinner,sunxi-pwm6";
			pinctrl-names = "active\0sleep";
			reg_base = <0x300a000>;
			pinctrl-0 = <0x88>;
			pinctrl-1 = <0x89>;
			status = "okay";
			linux,phandle = <0x78>;
			phandle = <0x78>;
		};

		pwm7@0300a000 {
			compatible = "allwinner,sunxi-pwm7";
			pinctrl-names = "active\0sleep";
			reg_base = <0x300a000>;
			pinctrl-0 = <0x8a>;
			pinctrl-1 = <0x8b>;
			status = "okay";
			linux,phandle = <0x79>;
			phandle = <0x79>;
		};

		pwm8@0300a000 {
			compatible = "allwinner,sunxi-pwm8";
			pinctrl-names = "active\0sleep";
			reg_base = <0x300a000>;
			pinctrl-0 = <0x8c>;
			pinctrl-1 = <0x8d>;
			status = "okay";
			linux,phandle = <0x7a>;
			phandle = <0x7a>;
		};

		pwm9@0300a000 {
			compatible = "allwinner,sunxi-pwm9";
			pinctrl-names = "active\0sleep";
			reg_base = <0x300a000>;
			pinctrl-0 = <0x8e>;
			pinctrl-1 = <0x8f>;
			status = "okay";
			linux,phandle = <0x7b>;
			phandle = <0x7b>;
		};

		boot_disp {
			compatible = "allwinner,boot_disp";
			linux,phandle = <0x117>;
			phandle = <0x117>;
		};

		vind@0 {
			compatible = "allwinner,sunxi-vin-media\0simple-bus";
			#address-cells = <0x02>;
			#size-cells = <0x02>;
			ranges;
			device_id = <0x00>;
			vind0_clk = <0x134fd900>;
			vind0_isp = <0xbebc200>;
			reg = <0x00 0x6600800 0x00 0x200 0x00 0x6600000 0x00 0x800>;
			interrupts = <0x00 0x5c 0x04>;
			clocks = <0x90 0x04 0x91 0x08 0x04 0x92 0x08 0x04 0x93 0x02>;
			pinctrl-names = "mclk0-default\0mclk0-sleep\0mclk1-default\0mclk1-sleep";
			pinctrl-0 = <0x94>;
			pinctrl-1 = <0x95>;
			pinctrl-2 = <0x96>;
			pinctrl-3 = <0x97>;
			status = "okay";
			linux,phandle = <0x118>;
			phandle = <0x118>;

			csi@0 {
				device_type = "csi0";
				compatible = "allwinner,sunxi-csi";
				reg = <0x00 0x6601000 0x00 0x1000>;
				interrupts = <0x00 0x4e 0x04>;
				device_id = <0x00>;
				iommus = <0x15 0x04 0x01>;
				status = "okay";
				linux,phandle = <0x119>;
				phandle = <0x119>;
			};

			csi@1 {
				device_type = "csi1";
				compatible = "allwinner,sunxi-csi";
				reg = <0x00 0x6602000 0x00 0x1000>;
				interrupts = <0x00 0x4f 0x04>;
				pinctrl-names = "default\0sleep";
				pinctrl-0 = <0x98>;
				pinctrl-1 = <0x99>;
				device_id = <0x01>;
				iommus = <0x15 0x04 0x01>;
				status = "okay";
				linux,phandle = <0x11a>;
				phandle = <0x11a>;
			};

			mipi@0 {
				compatible = "allwinner,sunxi-mipi";
				reg = <0x00 0x660c000 0x00 0x1000>;
				interrupts = <0x00 0x52 0x04>;
				device_id = <0x00>;
				status = "okay";
				linux,phandle = <0x11b>;
				phandle = <0x11b>;
			};

			isp@0 {
				compatible = "allwinner,sunxi-isp";
				reg = <0x00 0x2100000 0x00 0x800>;
				interrupts = <0x00 0x21 0x04>;
				device_id = <0x00>;
				iommus = <0x15 0x05 0x01>;
				status = "okay";
				linux,phandle = <0x11c>;
				phandle = <0x11c>;
			};

			isp@1 {
				compatible = "allwinner,sunxi-isp";
				device_id = <0x01>;
				status = "okay";
				linux,phandle = <0x11d>;
				phandle = <0x11d>;
			};

			scaler@0 {
				compatible = "allwinner,sunxi-scaler";
				reg = <0x00 0x2104000 0x00 0x400>;
				device_id = <0x00>;
				iommus = <0x15 0x05 0x01>;
				status = "okay";
				linux,phandle = <0x11e>;
				phandle = <0x11e>;
			};

			scaler@1 {
				compatible = "allwinner,sunxi-scaler";
				reg = <0x00 0x2104400 0x00 0x400>;
				device_id = <0x01>;
				iommus = <0x15 0x05 0x01>;
				status = "okay";
				linux,phandle = <0x11f>;
				phandle = <0x11f>;
			};

			scaler@2 {
				compatible = "allwinner,sunxi-scaler";
				reg = <0x00 0x2104800 0x00 0x400>;
				device_id = <0x02>;
				iommus = <0x15 0x05 0x01>;
				status = "okay";
				linux,phandle = <0x120>;
				phandle = <0x120>;
			};

			scaler@3 {
				compatible = "allwinner,sunxi-scaler";
				reg = <0x00 0x2104c00 0x00 0x400>;
				device_id = <0x03>;
				iommus = <0x15 0x05 0x01>;
				status = "okay";
				linux,phandle = <0x121>;
				phandle = <0x121>;
			};

			actuator@0 {
				device_type = "actuator0";
				compatible = "allwinner,sunxi-actuator";
				actuator0_name = "ad5820_act";
				actuator0_slave = <0x18>;
				actuator0_af_pwdn;
				actuator0_afvdd = "afvcc-csi";
				actuator0_afvdd_vol = <0x2ab980>;
				status = "disabled";
				linux,phandle = <0x9b>;
				phandle = <0x9b>;
			};

			flash@0 {
				device_type = "flash0";
				compatible = "allwinner,sunxi-flash";
				flash0_type = <0x02>;
				flash0_en;
				flash0_mode;
				flash0_flvdd = [00];
				flash0_flvdd_vol;
				device_id = <0x00>;
				status = "disabled";
				linux,phandle = <0x9a>;
				phandle = <0x9a>;
			};

			sensor@0 {
				device_type = "sensor0";
				compatible = "allwinner,sunxi-sensor";
				clocks = <0x91 0x08 0x04>;
				pinctrl-names = "mclk0-default\0mclk0-sleep";
				pinctrl-0 = <0x94>;
				pinctrl-1 = <0x95>;
				sensor0_mname = "gc2093_mipi";
				sensor0_twi_cci_id = <0x01>;
				sensor0_twi_addr = <0x6e>;
				sensor0_mclk_id = <0x00>;
				sensor0_pos = "rear";
				sensor0_isp_used = <0x01>;
				sensor0_fmt = <0x01>;
				sensor0_stby_mode = <0x00>;
				sensor0_vflip = <0x00>;
				sensor0_hflip = <0x00>;
				sensor0_iovdd-supply = <0x3b>;
				sensor0_iovdd_vol = <0x1b7740>;
				sensor0_avdd-supply = <0x3c>;
				sensor0_avdd_vol = <0x325aa0>;
				sensor0_dvdd-supply;
				sensor0_dvdd_vol = <0x124f80>;
				sensor0_power_en;
				sensor0_reset = <0x36 0x08 0x03 0x01 0x00 0x01 0x00>;
				sensor0_pwdn = <0x36 0x08 0x04 0x01 0x00 0x01 0x00>;
				flash_handle = <0x9a>;
				act_handle = <0x9b>;
				device_id = <0x00>;
				status = "disabled";
				linux,phandle = <0x122>;
				phandle = <0x122>;
			};

			sensor@1 {
				device_type = "sensor1";
				compatible = "allwinner,sunxi-sensor";
				clocks = <0x92 0x08 0x04>;
				pinctrl-names = "mclk1-default\0mclk1-sleep";
				pinctrl-0 = <0x96>;
				pinctrl-1 = <0x97>;
				sensor1_mname = "tp9950";
				sensor1_twi_cci_id = <0x00>;
				sensor1_twi_addr = <0x88>;
				sensor1_mclk_id = <0x01>;
				sensor1_pos = "front";
				sensor1_isp_used = <0x00>;
				sensor1_fmt = <0x00>;
				sensor1_stby_mode = <0x00>;
				sensor1_vflip = <0x00>;
				sensor1_hflip = <0x00>;
				sensor1_iovdd-supply = <0x3c>;
				sensor1_iovdd_vol = <0x1b7740>;
				sensor1_avdd-supply = <0x37>;
				sensor1_avdd_vol = <0x325aa0>;
				sensor1_dvdd-supply = <0x3e>;
				sensor1_dvdd_vol = <0x124f80>;
				sensor1_power_en;
				sensor1_reset = <0x36 0x04 0x0d 0x01 0x00 0x01 0x00>;
				sensor1_pwdn;
				flash_handle;
				act_handle;
				device_id = <0x01>;
				status = "okay";
				sensor1_sm_hs;
				sensor1_sm_vs;
				linux,phandle = <0x123>;
				phandle = <0x123>;
			};

			vinc@0 {
				device_type = "vinc0";
				compatible = "allwinner,sunxi-vin-core";
				reg = <0x00 0x6609000 0x00 0x200>;
				interrupts = <0x00 0x4a 0x04>;
				vinc0_csi_sel = <0x00>;
				vinc0_mipi_sel = <0x00>;
				vinc0_isp_sel = <0x00>;
				vinc0_rear_sensor_sel = <0x00>;
				vinc0_front_sensor_sel = <0x00>;
				vinc0_sensor_list = <0x00>;
				device_id = <0x00>;
				iommus = <0x15 0x04 0x01>;
				status = "okay";
				vinc0_isp_tx_ch = <0x00>;
				linux,phandle = <0x124>;
				phandle = <0x124>;
			};

			vinc@1 {
				device_type = "vinc1";
				compatible = "allwinner,sunxi-vin-core";
				reg = <0x00 0x6609200 0x00 0x200>;
				interrupts = <0x00 0x4b 0x04>;
				vinc1_csi_sel = <0x01>;
				vinc1_mipi_sel = <0xff>;
				vinc1_isp_sel = <0x01>;
				vinc1_rear_sensor_sel = <0x01>;
				vinc1_front_sensor_sel = <0x01>;
				vinc1_sensor_list = <0x00>;
				device_id = <0x01>;
				iommus = <0x15 0x04 0x01>;
				status = "okay";
				vinc1_isp_tx_ch = <0x00>;
				linux,phandle = <0x125>;
				phandle = <0x125>;
			};

			vinc@2 {
				device_type = "vinc2";
				compatible = "allwinner,sunxi-vin-core";
				reg = <0x00 0x6609400 0x00 0x200>;
				interrupts = <0x00 0x4c 0x04>;
				vinc2_csi_sel = <0x01>;
				vinc2_mipi_sel = <0xff>;
				vinc2_isp_sel = <0x00>;
				vinc2_rear_sensor_sel = <0x00>;
				vinc2_front_sensor_sel = <0x00>;
				vinc2_sensor_list = <0x00>;
				device_id = <0x02>;
				iommus = <0x15 0x04 0x01>;
				status = "disabled";
				vinc2_isp_tx_ch = <0x02>;
				linux,phandle = <0x126>;
				phandle = <0x126>;
			};

			vinc@3 {
				device_type = "vinc3";
				compatible = "allwinner,sunxi-vin-core";
				reg = <0x00 0x6609600 0x00 0x200>;
				interrupts = <0x00 0x4d 0x04>;
				vinc3_csi_sel = <0x01>;
				vinc3_mipi_sel = <0xff>;
				vinc3_isp_sel = <0x00>;
				vinc3_rear_sensor_sel = <0x00>;
				vinc3_front_sensor_sel = <0x00>;
				vinc3_sensor_list = <0x00>;
				device_id = <0x03>;
				iommus = <0x15 0x04 0x01>;
				status = "disabled";
				vinc3_isp_tx_ch = <0x03>;
				linux,phandle = <0x127>;
				phandle = <0x127>;
			};
		};

		vdevice@0 {
			compatible = "allwinner,sun8i-vdevice";
			device_type = "Vdevice";
			interrupt-parent = <0x36>;
			interrupts = <0x03 0x03 0x04>;
			pinctrl-names = "default";
			pinctrl-0 = <0x9c>;
			test-gpios = <0x36 0x02 0x03 0x01 0x02 0x02 0x01>;
			status = "disabled";
			linux,phandle = <0x128>;
			phandle = <0x128>;
		};

		ce@1904000 {
			compatible = "allwinner,sunxi-ce";
			device_name = "ce";
			reg = <0x00 0x1904000 0x00 0xa0 0x00 0x1904800 0x00 0xa0>;
			interrupts = <0x00 0x23 0x01 0x00 0x24 0x01>;
			clock-frequency = <0x11e1a300>;
			clocks = <0x9d 0x0e>;
			linux,phandle = <0x129>;
			phandle = <0x129>;
		};

		nmi@0x01f00c00 {
			#address-cells = <0x01>;
			#size-cells = <0x00>;
			compatible = "allwinner,sunxi-nmi";
			reg = <0x00 0x1f00c00 0x00 0x50>;
			nmi_irq_ctrl = <0x0c>;
			nmi_irq_en = <0x40>;
			nmi_irq_status = <0x10>;
			nmi_irq_mask = <0x50>;
			status = "okay";
			linux,phandle = <0x12a>;
			phandle = <0x12a>;
		};

		thermal_sensor {
			compatible = "allwinner,thermal_sensor";
			reg = <0x00 0x5070400 0x00 0x400>;
			interrupts = <0x00 0x01 0x00>;
			clocks = <0x08 0x9e>;
			sensor_num = <0x04>;
			combine_num = <0x04>;
			shut_temp = <0x1c138>;
			status = "okay";
			linux,phandle = <0x12b>;
			phandle = <0x12b>;

			ths_combine0 {
				compatible = "allwinner,ths_combine";
				#thermal-sensor-cells = <0x01>;
				combine_sensor_num = <0x01>;
				combine_sensor_type = "CPU";
				combine_sensor_temp_type = "max";
				combine_sensor_id = <0x00>;
				linux,phandle = <0x9f>;
				phandle = <0x9f>;
			};

			ths_combine1 {
				compatible = "allwinner,ths_combine";
				#thermal-sensor-cells = <0x01>;
				combine_sensor_num = <0x01>;
				combine_sensor_type = "VE";
				combine_sensor_temp_type = "max";
				combine_sensor_id = <0x01>;
				linux,phandle = <0xa2>;
				phandle = <0xa2>;
			};

			ths_combine2 {
				compatible = "allwinner,ths_combine";
				#thermal-sensor-cells = <0x01>;
				combine_sensor_num = <0x01>;
				combine_sensor_type = "ISP";
				combine_sensor_temp_type = "max";
				combine_sensor_id = <0x02>;
				linux,phandle = <0xa3>;
				phandle = <0xa3>;
			};

			ths_combine3 {
				compatible = "allwinner,ths_combine";
				#thermal-sensor-cells = <0x01>;
				combine_sensor_num = <0x01>;
				combine_sensor_type = "DDR";
				combine_sensor_temp_type = "max";
				combine_sensor_id = <0x03>;
				linux,phandle = <0xa4>;
				phandle = <0xa4>;
			};
		};

		cpu_budget_cool {
			compatible = "allwinner,budget_cooling";
			device_type = "cpu_budget_cooling";
			#cooling-cells = <0x02>;
			status = "okay";
			state_cnt = <0x02>;
			cluster_num = <0x01>;
			state0 = <0x10d880 0x01>;
			state1 = <0x927c0 0x01>;
			linux,phandle = <0xa1>;
			phandle = <0xa1>;
		};

		thermal-zones {

			cpu_thermal_zone {
				polling-delay-passive = <0x3e8>;
				polling-delay = <0x3e8>;
				thermal-sensors = <0x9f 0x00>;

				trips {

					t0 {
						temperature = <0x13880>;
						type = "passive";
						hysteresis = <0x00>;
						linux,phandle = <0xa0>;
						phandle = <0xa0>;
					};

					t2 {
						temperature = <0x1d4c0>;
						type = "critical";
						hysteresis = <0x00>;
						linux,phandle = <0x12c>;
						phandle = <0x12c>;
					};
				};

				cooling-maps {

					bind0 {
						contribution = <0x00>;
						trip = <0xa0>;
						cooling-device = <0xa1 0x01 0x01>;
					};
				};
			};

			ve_thermal_zone {
				polling-delay-passive = <0x3e8>;
				polling-delay = <0x2710>;
				thermal-sensors = <0xa2 0x01>;

				trips {

					t0 {
						temperature = <0x1d4c0>;
						type = "critical";
						hysteresis = <0x00>;
						linux,phandle = <0x12d>;
						phandle = <0x12d>;
					};
				};
			};

			isp_thermal_zone {
				polling-delay-passive = <0x3e8>;
				polling-delay = <0x2710>;
				thermal-sensors = <0xa3 0x02>;

				trips {

					t0 {
						temperature = <0x1d4c0>;
						type = "critical";
						hysteresis = <0x00>;
						linux,phandle = <0x12e>;
						phandle = <0x12e>;
					};
				};
			};

			ddr_thermal_zone {
				polling-delay-passive = <0x3e8>;
				polling-delay = <0x2710>;
				thermal-sensors = <0xa4 0x03>;

				trips {

					t0 {
						temperature = <0x1d4c0>;
						type = "critical";
						hysteresis = <0x00>;
						linux,phandle = <0x12f>;
						phandle = <0x12f>;
					};
				};
			};
		};

		gpadc {
			compatible = "allwinner,sunxi-gpadc";
			reg = <0x00 0x5070000 0x00 0x400>;
			interrupts = <0x00 0x00 0x00>;
			clocks = <0xa5>;
			status = "okay";
			channel_num = <0x02>;
			channel_select = <0x03>;
			channel_data_select = <0x00>;
			channel_compare_select = <0x03>;
			channel_cld_select = <0x03>;
			channel_chd_select = <0x00>;
			channel0_compare_lowdata = <0x19f0a0>;
			channel0_compare_higdata = <0x124f80>;
			channel1_compare_lowdata = <0x704e0>;
			channel1_compare_higdata = <0x124f80>;
			key_cnt = <0x05>;
			key0_vol = <0xd2>;
			key0_val = <0x1c>;
			key1_vol = <0x19a>;
			key1_val = <0x66>;
			key2_vol = <0x24e>;
			key2_val = <0x73>;
			key3_vol = <0x2ee>;
			key3_val = <0x8b>;
			key4_vol = <0x370>;
			key4_val = <0x72>;
			linux,phandle = <0x130>;
			phandle = <0x130>;
		};

		eth@05020000 {
			compatible = "allwinner,sunxi-gmac";
			reg = <0x00 0x5020000 0x00 0xffff 0x00 0x3000030 0x00 0x04>;
			interrupts = <0x00 0x1b 0x04>;
			interrupt-names = "gmacirq";
			clocks = <0xa6 0xa7>;
			clock-names = "gmac\0ephy";
			pinctrl-names = "default\0sleep";
			pinctrl-0 = <0xa8>;
			pinctrl-1 = <0xa9>;
			phy-mode = "rmii";
			use_ephy25m = <0x01>;
			tx-delay = <0x07>;
			rx-delay = <0x1f>;
			phy-rst = <0x36 0x03 0x13 0x01 0x01 0x01 0x00>;
			gmac-power0;
			gmac-power1;
			gmac-power2;
			status = "okay";
			linux,phandle = <0x131>;
			phandle = <0x131>;
		};

		standby_param {
			vdd-cpu = <0x04>;
			vdd-sys = <0x04>;
			vcc-io = <0x01>;
			vcc-pll = <0x80>;
			linux,phandle = <0x132>;
			phandle = <0x132>;
		};

		card0_boot_para {
			device_type = "card0_boot_para";
			card_ctrl = <0x00>;
			card_high_speed = <0x01>;
			card_line = <0x04>;
			time_pwroff_ms = <0xc8>;
			pinctrl-1 = <0x66>;
			status = "okay";
			pinctrl-0 = <0x13c>;
		};

		product {
			device_type = "product";
			version = "100";
			machine = "evb";
		};

		platform {
			device_type = "platform";
			debug_mode = <0x08>;
			eraseflag = <0x00>;
		};

		target {
			device_type = "target";
			boot_clock = <0x3f0>;
			storage_type = <0x03>;
		};

		power_sply {
			device_type = "power_sply";
			dcdc1_vol = <0xf4f24>;
			dcdc2_vol = <0x18a24>;
			dcdc3_vol = <0x18a4c>;
			dcdc4_vol = <0xf481c>;
			dcdc5_vol = <0xf46f0>;
			aldo1_vol = <0xf4948>;
			aldo2_vol = <0xf4f24>;
			aldo3_vol = <0xf4f24>;
			aldo4_vol = <0xf4f24>;
			bldo1_vol = <0xf4948>;
			bldo2_vol = <0xf4f24>;
			cpusldo_vol = <0x18a24>;
			dldo1_vol = <0xf4f24>;
			dldo2_vol = <0xf4f24>;
		};

		axp152_power_sply {
			device_type = "axp152_power_sply";
			ldo0_vol = <0xf55c8>;
		};

		card_boot {
			device_type = "card_boot";
			logical_start = <0xa000>;
			sprite_gpio0;
		};

		pm_para {
			device_type = "pm_para";
			standby_mode = <0x01>;
		};

		card2_boot_para {
			device_type = "card2_boot_para";
			card_ctrl = <0x02>;
			card_high_speed = <0x01>;
			card_line = <0x08>;
			pinctrl-0 = <0x13d>;
			sdc_ex_dly_used = <0x02>;
		};

		twi_para {
			device_type = "twi_para";
			twi_port = <0x00>;
			pinctrl-0 = <0x13e>;
		};

		uart_para {
			device_type = "uart_para";
			uart_debug_port = <0x00>;
			pinctrl-0 = <0x13f>;
		};

		jtag_para {
			device_type = "jtag_para";
			jtag_enable = <0x00>;
			pinctrl-0 = <0x142>;
		};

		clock {
			device_type = "clock";
			pll4 = <0x12c>;
			pll6 = <0x258>;
			pll8 = <0x168>;
			pll9 = <0x129>;
			pll10 = <0x108>;
		};

		charger0 {
			device_type = "charger0";
			pmu_safe_vol = <0xea6>;
		};

		ctp {
			device_type = "ctp";
			ctp_twi_id = <0x03>;
			ctp_name = "gt9xxnew_ts";
			ctp_cfg_id = <0x00>;
			ctp_screen_max_x = <0x640>;
			ctp_screen_max_y = <0x258>;
			ctp_int_port = <0xd5 0x0b 0x02 0x06 0xffffffff 0xffffffff 0x00>;
			ctp_reset_port = <0xd5 0x0b 0x04 0x01 0xffffffff 0xffffffff 0x00>;
		};

		sunxi-gpio-ir {
			device_type = "sunxi-gpio-ir";
			compatible = "allwinner,gpio-ir-rx";
			gpio-rx = <0xd5 0x0b 0x05 0x06 0x01 0xffffffff 0xffffffff>;
		};

		gpioled {
			device_type = "gpioled";
			compatible = "gpio-leds";

			ahd_12_pwr {
				device_type = "ahd_12_pwr";
				label = "ahd_12_pwr";
				gpios = <0x36 0x04 0x14 0x01 0xffffffff 0xffffffff 0x01>;
				linux,default-trigger = "none";
				default-state = "on";
			};

			bt_en {
				device_type = "bt_en";
				label = "bt_en";
				gpios = <0x36 0x07 0x00 0x01 0xffffffff 0xffffffff 0x01>;
				linux,default-trigger = "none";
				default-state = "on";
			};

			spk_en {
				device_type = "spk_en";
				label = "spk_en";
				gpios = <0xd5 0x0b 0x03 0x01 0xffffffff 0xffffffff 0x01>;
				linux,default-trigger = "none";
				default-state = "off";
			};
		};

		partitions {
			device_type = "partitions";

			boot {
				device_type = "boot";
				offset = <0x20>;
				size = <0x1480>;
			};

			rootfs {
				device_type = "rootfs";
				offset = <0x14a0>;
				size = <0x1480>;
			};

			extrootfs {
				device_type = "extrootfs";
				offset = <0x2920>;
				size = <0x800>;
			};

			extend {
				device_type = "extend";
				offset = <0x3120>;
				size = <0x4680>;
			};

			overlay {
				device_type = "overlay";
				offset = <0x77a0>;
				size = <0x400>;
			};

			bootlogo {
				device_type = "bootlogo";
				offset = <0x7ba0>;
				size = <0x100>;
			};

			misc {
				device_type = "misc";
				offset = <0x7ca0>;
				size = <0x80>;
			};

			UDISK {
				device_type = "UDISK";
				offset = <0x7d20>;
				size = <0x00>;
			};
		};
	};

	aliases {
		serial0 = "/soc@03000000/uart@05000000\0/soc@03000000/uart@05000000";
		serial1 = "/soc@03000000/uart@05000400\0/soc@03000000/uart@05000400";
		serial2 = "/soc@03000000/uart@05000800\0/soc@03000000/uart@05000800";
		serial3 = "/soc@03000000/uart@05000c00\0/soc@03000000/uart@05000c00";
		twi0 = "/soc@03000000/twi@0x05002000\0/soc@03000000/twi@0x05002000";
		twi1 = "/soc@03000000/twi@0x05002400\0/soc@03000000/twi@0x05002400";
		twi2 = "/soc@03000000/twi@0x05002800\0/soc@03000000/twi@0x05002800";
		twi3 = "/soc@03000000/twi@0x05002c00\0/soc@03000000/twi@0x05002c00";
		twi4 = "/soc@03000000/twi@0x07081400\0/soc@03000000/twi@0x07081400";
		spi0 = "/soc@03000000/spi@05010000\0/soc@03000000/spi@05010000";
		spi1 = "/soc@03000000/spi@05011000\0/soc@03000000/spi@05011000";
		spi2 = "/soc@03000000/spi@05012000\0/soc@03000000/spi@05012000";
		gmac0 = "/soc@03000000/eth@05020000\0/soc@03000000/eth@05020000";
		global_timer0 = "/soc@03000000/timer@03009000\0/soc@03000000/timer@03009000";
		mmc0 = "/soc@03000000/sdmmc@04020000\0/soc@03000000/sdmmc@04020000";
		mmc2 = "/soc@03000000/sdmmc@04022000\0/soc@03000000/sdmmc@04022000";
		disp = "/soc@03000000/disp@01000000\0/soc@03000000/disp@01000000";
		lcd0 = "/soc@03000000/lcd0@01c0c000\0/soc@03000000/lcd0@01c0c000";
		pwm = "/soc@03000000/pwm@0300a000\0/soc@03000000/pwm@0300a000";
		pwm0 = "/soc@03000000/pwm0@0300a000\0/soc@03000000/pwm0@0300a000";
		pwm1 = "/soc@03000000/pwm1@0300a000\0/soc@03000000/pwm1@0300a000";
		pwm2 = "/soc@03000000/pwm2@0300a000\0/soc@03000000/pwm2@0300a000";
		pwm3 = "/soc@03000000/pwm3@0300a000\0/soc@03000000/pwm3@0300a000";
		pwm4 = "/soc@03000000/pwm4@0300a000\0/soc@03000000/pwm4@0300a000";
		pwm5 = "/soc@03000000/pwm5@0300a000\0/soc@03000000/pwm5@0300a000";
		pwm6 = "/soc@03000000/pwm6@0300a000\0/soc@03000000/pwm6@0300a000";
		pwm7 = "/soc@03000000/pwm7@0300a000\0/soc@03000000/pwm7@0300a000";
		pwm8 = "/soc@03000000/pwm8@0300a000\0/soc@03000000/pwm8@0300a000";
		pwm9 = "/soc@03000000/pwm9@0300a000\0/soc@03000000/pwm9@0300a000";
		boot_disp = "/soc@03000000/boot_disp\0/soc@03000000/boot_disp";
		pmu0 = "/soc@03000000/twi@0x07081400/pmu@0\0/soc@03000000/twi@0x07081400/pmu@0";
		standby_param = "/soc@03000000/standby_param\0/soc@03000000/standby_param";
	};

	chosen {
		bootargs = "earlyprintk=sunxi-uart,0x05000c00 initcall_debug=0 console=ttyS0,115200 loglevel=1 root=/dev/mtdblock2 init=/pseudo_init partitions=boot@mtdblock1:rootfs@mtdblock2:extrootfs@mtdblock3:extend@mtdblock4:overlay@mtdblock5:bootlogo@mtdblock6:misc@mtdblock7 cma=16M androidboot.hardware=sun8iw19p1 boot_type=3 androidboot.boot_type=3 gpt=1 mbr_offset=311296 disp_reserve=262144,0x46400000 bootreason=button";
		linux,initrd-start = <0x00 0x00>;
		linux,initrd-end = <0x00 0x00>;
	};

	cpus {
		enable-method = "allwinner,sun8iw19p1";
		#address-cells = <0x01>;
		#size-cells = <0x00>;

		cpu@0 {
			device_type = "cpu";
			compatible = "arm,cortex-a7";
			reg = <0x00>;
			enable-method = "psci";
			clocks = <0xaa>;
			clock-frequency = <0x3c14dc00>;
			clock-latency = <0x1e8480>;
			operating-points-v2 = <0xab>;
			cpu-idle-states = <0xac 0xad 0xae>;
			cooling-min-level = <0x05>;
			cooling-max-level = <0x00>;
			#cooling-cells = <0x02>;
			dynamic-power-coefficient = <0x96>;
			cpu-supply = <0x39>;
			linux,phandle = <0x133>;
			phandle = <0x133>;
		};

		idle-states {
			entry-method = "arm,psci";

			cpu-sleep-0 {
				compatible = "arm,idle-state";
				arm,psci-suspend-param = <0x10000>;
				entry-latency-us = <0x2d>;
				exit-latency-us = <0x5a>;
				min-residency-us = <0xbb8>;
				local-timer-stop;
				linux,phandle = <0xac>;
				phandle = <0xac>;
			};

			cluster-sleep-0 {
				compatible = "arm,idle-state";
				arm,psci-suspend-param = <0x1010000>;
				entry-latency-us = <0x37>;
				exit-latency-us = <0x23a>;
				min-residency-us = <0x4268>;
				local-timer-stop;
				linux,phandle = <0xad>;
				phandle = <0xad>;
			};

			sys-sleep-0 {
				compatible = "arm,idle-state";
				arm,psci-suspend-param = <0x2010000>;
				entry-latency-us = <0xffffffff>;
				exit-latency-us = <0xffffffff>;
				min-residency-us = <0xffffffff>;
				local-timer-stop;
				linux,phandle = <0xae>;
				phandle = <0xae>;
			};
		};
	};

	psci {
		compatible = "arm,psci-1.0";
		method = "smc";
	};

	n_brom {
		compatible = "allwinner,n-brom";
		reg = <0x00 0x00 0x00 0xc000>;
	};

	s_brom {
		compatible = "allwinner,s-brom";
		reg = <0x00 0x00 0x00 0x10000>;
	};

	sram_ctrl {
		device_type = "sram_ctrl";
		compatible = "allwinner,sram_ctrl";
		reg = <0x00 0x3000000 0x00 0x100>;
	};

	sram_a1 {
		compatible = "allwinner,sram_a1";
		reg = <0x00 0x10000 0x00 0x10000>;
	};

	sram_a2 {
		compatible = "allwinner,sram_a2";
		reg = <0x00 0x40000 0x00 0x14000>;
	};

	prcm {
		compatible = "allwinner,prcm";
		reg = <0x00 0x1f01400 0x00 0x400>;
	};

	cpuscfg {
		compatible = "allwinner,cpuscfg";
		reg = <0x00 0x1f01c00 0x00 0x400>;
	};

	ion {
		compatible = "allwinner,sunxi-ion";

		heap_sys_user@0 {
			compatible = "allwinner,sys_user";
			heap-name = "sys_user";
			heap-id = <0x00>;
			heap-base = <0x00>;
			heap-size = <0x00>;
			heap-type = "ion_system";
		};

		heap_sys_contig@0 {
			compatible = "allwinner,sys_contig";
			heap-name = "sys_contig";
			heap-id = <0x01>;
			heap-base = <0x00>;
			heap-size = <0x00>;
			heap-type = "ion_contig";
		};

		heap_cma@0 {
			compatible = "allwinner,cma";
			heap-name = "cma";
			heap-id = <0x04>;
			heap-base = <0x00>;
			heap-size = <0x00>;
			heap-type = "ion_cma";
		};
	};

	dram {
		compatible = "allwinner,dram";
		device_type = "dram";
		clocks = <0x07>;
		clock-names = "pll_ddr0";
		dram_clk = <0x318>;
		dram_type = <0x03>;
		dram_zq = <0xbfb>;
		dram_odt_en = <0x00>;
		dram_para1 = <0x10f2>;
		dram_para2 = <0x00>;
		dram_mr0 = <0x1c70>;
		dram_mr1 = <0x02>;
		dram_mr2 = <0x18>;
		dram_mr3 = <0x00>;
		dram_tpr0 = <0x4a2195>;
		dram_tpr1 = <0x2423190>;
		dram_tpr2 = <0x8b061>;
		dram_tpr3 = <0xb4787896>;
		dram_tpr4 = <0x00>;
		dram_tpr5 = <0x48484848>;
		dram_tpr6 = <0x48>;
		dram_tpr7 = <0x1621121e>;
		dram_tpr8 = <0x00>;
		dram_tpr9 = <0x00>;
		dram_tpr10 = <0x00>;
		dram_tpr11 = <0x540000>;
		dram_tpr12 = <0x45>;
		dram_tpr13 = <0x34022900>;
		linux,phandle = <0x134>;
		phandle = <0x134>;
	};

	memory@40000000 {
		device_type = "memory";
		reg = <0x00 0x40000000 0x00 0x8000000>;
	};

	interrupt-controller@03020000 {
		compatible = "arm,cortex-a15-gic\0arm,cortex-a9-gic";
		#interrupt-cells = <0x03>;
		#address-cells = <0x00>;
		device_type = "gic";
		interrupt-controller;
		reg = <0x00 0x3021000 0x00 0x1000 0x00 0x3022000 0x00 0x2000 0x00 0x3024000 0x00 0x2000 0x00 0x3026000 0x00 0x2000>;
		interrupts = <0x01 0x09 0xf04>;
		interrupt-parent = <0xaf>;
		linux,phandle = <0xaf>;
		phandle = <0xaf>;
	};

	intc-nmi@07010320 {
		compatible = "allwinner,sun8i-nmi";
		interrupt-parent = <0xaf>;
		#interrupt-cells = <0x02>;
		#address-cells = <0x00>;
		interrupt-controller;
		reg = <0x00 0x7010320 0x00 0x0c>;
		pad-control-v1 = <0x7000208>;
		interrupts = <0x00 0x68 0x04>;
		linux,phandle = <0x35>;
		phandle = <0x35>;
	};

	interrupt-controller@0 {
		compatible = "allwinner,sunxi-wakeupgen";
		interrupt-controller;
		#interrupt-cells = <0x03>;
		interrupt-parent = <0xaf>;
		linux,phandle = <0x01>;
		phandle = <0x01>;
	};

	sunxi-sid@03006000 {
		compatible = "allwinner,sunxi-sid";
		device_type = "sid";
		reg = <0x00 0x3006000 0x00 0x200>;
		linux,phandle = <0x135>;
		phandle = <0x135>;
	};

	sunxi-chipid@03006200 {
		compatible = "allwinner,sunxi-chipid";
		device_type = "chipid";
		reg = <0x00 0x3006200 0x00 0xc0>;
		linux,phandle = <0x136>;
		phandle = <0x136>;
	};

	timer {
		compatible = "arm,armv7-timer";
		interrupts = <0x01 0x0d 0x308 0x01 0x0e 0x308 0x01 0x0b 0x308 0x01 0x0a 0x308>;
		clock-frequency = <0x16e3600>;
		arm,cpu-registers-not-fw-configured;
		interrupt-parent = <0xaf>;
	};

	pmu {
		compatible = "arm,cortex-a7-pmu";
		interrupts = <0x00 0x8c 0x04>;
	};

	dramfreq {
		compatible = "allwinner,sunxi-dramfreq";
		reg = <0x00 0x1c62000 0x00 0x1000 0x00 0x1c63000 0x00 0x1000 0x00 0x1c20000 0x00 0x800>;
		interrupts = <0x00 0x45 0x04>;
		status = "okay";
	};

	uboot {
		linux,phandle = <0x137>;
		phandle = <0x137>;
	};

	iommu@030f0000 {
		compatible = "allwinner,sunxi-iommu";
		reg = <0x00 0x30f0000 0x00 0x1000>;
		interrupts = <0x00 0x5f 0x04>;
		interrupt-names = "iommu-irq";
		clocks = <0xb0>;
		clock-names = "iommu";
		#iommu-cells = <0x02>;
		status = "okay";
		linux,phandle = <0x15>;
		phandle = <0x15>;
	};

	mbus-controller@047FA000 {
		compatible = "allwinner,sun8i-mbus";
		reg = <0x00 0x4002000 0x00 0x1000>;
		#mbus-cells = <0x01>;
		linux,phandle = <0x138>;
		phandle = <0x138>;
	};

	ac200 {
		compatible = "allwinner,sunxi-ac200";
		pinctrl-names = "active\0sleep";
		status = "okay";
		linux,phandle = <0x139>;
		phandle = <0x139>;
	};

	ramoops@0x48106000 {
		compatible = "ramoops";
		reg = <0x00 0x48106000 0x00 0x60000>;
		record-size = <0x20000>;
		console-size = <0x20000>;
		pmsg-size = <0x20000>;
	};

	cpucfg@09010000 {
		compatible = "allwinner,sunxi-cpucfg";
		reg = <0x00 0x9010000 0x00 0xc8>;
	};

	opp_dvfs_table {
		cluster_num = <0x01>;
		opp_table_count = <0x01>;
		linux,phandle = <0x13a>;
		phandle = <0x13a>;

		opp_l_table0 {
			compatible = "allwinner,opp_l_table0";
			opp_count = <0x06>;
			opp-shared;
			linux,phandle = <0xab>;
			phandle = <0xab>;

			op00 {
				opp-hz = <0x00 0x23c34600>;
				opp-microvolt = <0xdbba0>;
				axi-bus-divide-ratio = <0x03>;
				clock-latency-ns = <0x1e8480>;
			};

			opp01 {
				opp-hz = <0x00 0x30a32c00>;
				opp-microvolt = <0xdbba0>;
				axi-bus-divide-ratio = <0x03>;
				clock-latency-ns = <0x1e8480>;
			};

			opp02 {
				opp-hz = <0x00 0x365c0400>;
				opp-microvolt = <0xdbba0>;
				axi-bus-divide-ratio = <0x03>;
				clock-latency-ns = <0x1e8480>;
			};

			opp03 {
				opp-hz = <0x00 0x3c14dc00>;
				opp-microvolt = <0xdbba0>;
				axi-bus-divide-ratio = <0x03>;
				clock-latency-ns = <0x1e8480>;
			};
		};
	};

	wlan {
		compatible = "allwinner,sunxi-wlan";
		clocks = <0xb1>;
		wlan_busnum = <0x01>;
		wakeup_source = <0x00>;
		wlan_power_num = <0x00>;
		wlan_regon = <0x36 0x06 0x06 0x01 0x00 0x01 0x00>;
		wlan_hostwake = <0x36 0x06 0x07 0x00 0x00 0x01 0x00>;
		status = "okay";
		linux,phandle = <0xb2>;
		phandle = <0xb2>;
	};

	axp2101-parameter {
		select = "battery-modelnew";
		linux,phandle = <0x13b>;
		phandle = <0x13b>;

		battery-model {
			parameter = <0x1f50000 0xfb0000fb 0x1e3201 0x1404d804 0x74fd580b 0xb3103ffb 0xc800be03 0x4e063f06 0x20ad30f 0x740f3109 0xe50eb90e 0xc004be04 0xbb09b40e 0xa00e9209 0x790e4c0e 0x2703fc03 0xd508bc0d 0x9c0d5506 0xb82e242e 0x2e242e24 0xc5987e66 0x4e44381a 0x120af600 0xf600f6 0xfb0000 0xfb0000fb 0xf600 0xf600f6 0xfb0000 0xfb0000fb 0xf600 0xf600f6>;
		};

		battery-modelnew {
			parameter = <0x1f54000 0x1b1e280f 0xc1e3202 0x14050a04 0x7402d00d 0xa71036fc 0x1801ea07 0xc005bf05 0x920a7e0f 0x470f1009 0xe50ec40e 0xc704c004 0xba09b30e 0xa20e9f09 0x960e7d0e 0x79046a04 0x6809610e 0x150d7607 0x31472120 0x18090e04 0xc5987e66 0x4e44381a 0x120af600 0xf600f6 0xfb0000 0xfb0000fb 0xf600 0xf600f6 0xfb0000 0xfb0000fb 0xf600 0xf600f6>;
		};
	};

	tc_overlay {

		hd_v1 {

			fragment@0 {
				target = <0xb2>;

				overlay {
					wlan_regon = <0x36 0x02 0x09 0x01 0x00 0x01 0x00>;
					wlan_hostwake = <0x36 0x02 0x0a 0x00 0x00 0x01 0x00>;
				};
			};

			fragment@1 {
				target = <0x1b>;

				overlay {
					allwinner,pins = "PG6\0PG7";
					allwinner,pname = "uart1_tx\0uart1_rx";
					allwinner,function = "uart1";
					allwinner,muxsel = <0x05>;
					allwinner,drive = <0x01>;
					allwinner,pull = <0x01>;
				};
			};

			fragment@2 {
				target = <0x1c>;

				overlay {
					allwinner,pins = "PG6\0PG7";
					allwinner,function = "io_disabled";
					allwinner,muxsel = <0x07>;
					allwinner,drive = <0x01>;
					allwinner,pull = <0x00>;
				};
			};

			fragment@3 {
				target = <0xb3>;

				overlay {
					uart1_type = <0x02>;
					status = "okay";
				};
			};
		};

		hd_v2 {
			parent = "hd_v1";

			fragment@0 {
				target = <0xb4>;

				overlay {

					daudio@0x05091000 {
						mclk_div = <0x02>;
					};

					sound@2 {
						daudio_master = <0x01>;
						sunxi,snddaudio-codec = "es8388.0-0010";
						sunxi,snddaudio-codec-dai = "ES8388 HiFi";
					};
				};
			};

			fragment@1 {
				target = <0xb5>;

				overlay {

					es7243e {
						status = "disabled";
					};

					es8388 {
						status = "okay";
					};
				};
			};

			fragment@2 {
				target = <0x36>;

				overlay {

					daudio1@0 {
						allwinner,drive = <0x03>;
					};

					daudio1_sleep@0 {
						allwinner,pins = "PD11\0PD12\0PD13\0PD14\0PD15\0PD16\0PD17";
					};
				};
			};
		};
	};

	__symbols__ {
		clk_losc = "/clocks/losc";
		clk_iosc = "/clocks/iosc";
		clk_hosc = "/clocks/hosc";
		clk_pll_periph0div25m = "/clocks/pll_periph0div25m";
		clk_osc48m = "/clocks/osc48m";
		clk_pll_cpu = "/clocks/pll_cpu";
		clk_pll_ddr0 = "/clocks/pll_ddr0";
		clk_pll_periph0 = "/clocks/pll_periph0";
		clk_pll_uni = "/clocks/pll_uni";
		clk_pll_video0 = "/clocks/pll_video0";
		clk_pll_audio = "/clocks/pll_audio";
		clk_pll_csi = "/clocks/pll_csi";
		clk_pll_periph0x2 = "/clocks/pll_periph0x2";
		clk_periph32k = "/clocks/periph32k";
		clk_pll_unix2 = "/clocks/pll_unix2";
		clk_pll_audiox4 = "/clocks/pll_audiox4";
		clk_pll_audiox2 = "/clocks/pll_audiox2";
		clk_pll_video0x4 = "/clocks/pll_video0x4";
		clk_mbus = "/clocks/mbus";
		clk_hoscd2 = "/clocks/hoscd2";
		clk_osc48md4 = "/clocks/osc48md4";
		clk_cpu = "/clocks/cpu";
		clk_axi = "/clocks/axi";
		clk_cpuapb = "/clocks/cpuapb";
		clk_psi = "/clocks/psi";
		clk_ahb1 = "/clocks/ahb1";
		clk_ahb2 = "/clocks/ahb2";
		clk_ahb3 = "/clocks/ahb3";
		clk_apb1 = "/clocks/apb1";
		clk_apb2 = "/clocks/apb2";
		clk_de = "/clocks/de";
		clk_g2d = "/clocks/g2d";
		clk_ve = "/clocks/ve";
		clk_ce = "/clocks/ce";
		clk_eise = "/clocks/eise";
		clk_nna = "/clocks/nna";
		clk_nna_rst = "/clocks/nna_rts";
		clk_isp = "/clocks/isp";
		clk_dma = "/clocks/dma";
		clk_hstimer = "/clocks/hstimer";
		clk_avs = "/clocks/avs";
		clk_dbgsys = "/clocks/dbgsys";
		clk_pwm = "/clocks/pwm";
		clk_iommu = "/clocks/iommu";
		clk_sdram = "/clocks/sdram";
		clk_sdmmc0_mod = "/clocks/sdmmc0_mod";
		clk_sdmmc0_bus = "/clocks/sdmmc0_bus";
		clk_sdmmc0_rst = "/clocks/sdmmc0_rst";
		clk_sdmmc1_mod = "/clocks/sdmmc1_mod";
		clk_sdmmc1_bus = "/clocks/sdmmc1_bus";
		clk_sdmmc1_rst = "/clocks/sdmmc1_rst";
		clk_sdmmc2_mod = "/clocks/sdmmc2_mod";
		clk_sdmmc2_bus = "/clocks/sdmmc2_bus";
		clk_sdmmc2_rst = "/clocks/sdmmc2_rst";
		clk_uart0 = "/clocks/uart0";
		clk_uart1 = "/clocks/uart1";
		clk_uart2 = "/clocks/uart2";
		clk_uart3 = "/clocks/uart3";
		clk_twi0 = "/clocks/twi0";
		clk_twi1 = "/clocks/twi1";
		clk_twi2 = "/clocks/twi2";
		clk_twi3 = "/clocks/twi3";
		clk_spi0 = "/clocks/spi0";
		clk_spi1 = "/clocks/spi1";
		clk_spi2 = "/clocks/spi2";
		clk_ephy_25m = "/clocks/ephy_25m";
		clk_gmac = "/clocks/gmac";
		clk_gpadc = "/clocks/gpadc";
		clk_ths = "/clocks/ths";
		clk_i2s0 = "/clocks/i2s0";
		clk_i2s1 = "/clocks/i2s1";
		clk_codec_1x = "/clocks/codec_1x";
		clk_codec_4x = "/clocks/codec_4x";
		clk_usbphy0 = "/clocks/usbphy0";
		clk_usbohci0 = "/clocks/usbohci0";
		clk_usbohci0_12m = "/clocks/usbohci0_12m";
		clk_usbehci0 = "/clocks/usbehci0";
		clk_usbotg = "/clocks/usbotg";
		clk_mipi_dphy0 = "/clocks/mipi_dphy0";
		clk_mipi_host0 = "/clocks/mipi_host0";
		clk_display_top = "/clocks/display_top";
		clk_tcon_lcd = "/clocks/tcon_lcd";
		clk_csi_top = "/clocks/csi_top";
		clk_csi_master0 = "/clocks/csi_master0";
		clk_csi_master1 = "/clocks/csi_master1";
		clk_dspo = "/clocks/dspo";
		clk_pio = "/clocks/pio";
		clk_cpurowc = "/clocks/cpurowc";
		clk_stwi = "/clocks/stwi";
		clk_losc_out = "/clocks/losc_out";
		clk_cpurcpus_pll = "/clocks/cpurcpus_pll";
		clk_cpurcpus = "/clocks/cpurcpus";
		clk_cpurahbs = "/clocks/cpurahbs";
		clk_cpurapbs1 = "/clocks/cpurapbs1";
		clk_cpurapbs2_pll = "/clocks/cpurapbs2_pll";
		clk_cpurapbs2 = "/clocks/cpurapbs2";
		clk_cpurpio = "/clocks/cpurpio";
		clk_spwm = "/clocks/spwm";
		clk_dcxo_out = "/clocks/dcxo_out";
		soc = "/soc@03000000";
		r_pio = "/soc@03000000/pinctrl@07022000";
		s_twi0_pins_a = "/soc@03000000/pinctrl@07022000/s_twi0@0";
		s_twi0_pins_b = "/soc@03000000/pinctrl@07022000/s_twi0@1";
		pio = "/soc@03000000/pinctrl@0300b000";
		vdevice_pins_a = "/soc@03000000/pinctrl@0300b000/vdevice@0";
		uart0_pins_a = "/soc@03000000/pinctrl@0300b000/uart0@0";
		uart0_pins_b = "/soc@03000000/pinctrl@0300b000/uart0@1";
		uart1_pins_a = "/soc@03000000/pinctrl@0300b000/uart1@0";
		uart1_pins_b = "/soc@03000000/pinctrl@0300b000/uart1@1";
		uart2_pins_a = "/soc@03000000/pinctrl@0300b000/uart2@0";
		uart2_pins_b = "/soc@03000000/pinctrl@0300b000/uart2@1";
		uart3_pins_a = "/soc@03000000/pinctrl@0300b000/uart3@0";
		uart3_pins_b = "/soc@03000000/pinctrl@0300b000/uart3@1";
		twi0_pins_a = "/soc@03000000/pinctrl@0300b000/twi0@0";
		twi0_pins_b = "/soc@03000000/pinctrl@0300b000/twi0@1";
		twi1_pins_a = "/soc@03000000/pinctrl@0300b000/twi1@0";
		twi1_pins_b = "/soc@03000000/pinctrl@0300b000/twi1@1";
		twi2_pins_a = "/soc@03000000/pinctrl@0300b000/twi2@0";
		twi2_pins_b = "/soc@03000000/pinctrl@0300b000/twi2@1";
		twi3_pins_a = "/soc@03000000/pinctrl@0300b000/twi3@0";
		twi3_pins_b = "/soc@03000000/pinctrl@0300b000/twi3@1";
		pwm0_pins_a = "/soc@03000000/pinctrl@0300b000/pwm0@0";
		pwm0_pins_b = "/soc@03000000/pinctrl@0300b000/pwm0@1";
		pwm1_pins_a = "/soc@03000000/pinctrl@0300b000/pwm1@0";
		pwm1_pins_b = "/soc@03000000/pinctrl@0300b000/pwm1@1";
		pwm2_pins_a = "/soc@03000000/pinctrl@0300b000/pwm2@0";
		pwm2_pins_b = "/soc@03000000/pinctrl@0300b000/pwm2@1";
		pwm3_pins_a = "/soc@03000000/pinctrl@0300b000/pwm3@0";
		pwm3_pins_b = "/soc@03000000/pinctrl@0300b000/pwm3@1";
		pwm4_pins_a = "/soc@03000000/pinctrl@0300b000/pwm4@0";
		pwm4_pins_b = "/soc@03000000/pinctrl@0300b000/pwm4@1";
		pwm5_pins_a = "/soc@03000000/pinctrl@0300b000/pwm5@0";
		pwm5_pins_b = "/soc@03000000/pinctrl@0300b000/pwm5@1";
		pwm6_pins_a = "/soc@03000000/pinctrl@0300b000/pwm6@0";
		pwm6_pins_b = "/soc@03000000/pinctrl@0300b000/pwm6@1";
		pwm7_pins_a = "/soc@03000000/pinctrl@0300b000/pwm7@0";
		pwm7_pins_b = "/soc@03000000/pinctrl@0300b000/pwm7@1";
		pwm8_pins_a = "/soc@03000000/pinctrl@0300b000/pwm8@0";
		pwm8_pins_b = "/soc@03000000/pinctrl@0300b000/pwm8@1";
		pwm9_pins_a = "/soc@03000000/pinctrl@0300b000/pwm9@0";
		pwm9_pins_b = "/soc@03000000/pinctrl@0300b000/pwm9@1";
		ts0_pins_a = "/soc@03000000/pinctrl@0300b000/ts0@0";
		ts0_pins_b = "/soc@03000000/pinctrl@0300b000/ts0_sleep@0";
		ts1_pins_a = "/soc@03000000/pinctrl@0300b000/ts1@0";
		ts1_pins_b = "/soc@03000000/pinctrl@0300b000/ts1_sleep@0";
		ts2_pins_a = "/soc@03000000/pinctrl@0300b000/ts2@0";
		ts2_pins_b = "/soc@03000000/pinctrl@0300b000/ts2_sleep@0";
		ts3_pins_a = "/soc@03000000/pinctrl@0300b000/ts3@0";
		ts3_pins_b = "/soc@03000000/pinctrl@0300b000/ts3_sleep@0";
		spi0_pins_a = "/soc@03000000/pinctrl@0300b000/spi0@0";
		spi0_pins_b = "/soc@03000000/pinctrl@0300b000/spi0@1";
		spi0_pins_c = "/soc@03000000/pinctrl@0300b000/spi0@2";
		spi1_pins_a = "/soc@03000000/pinctrl@0300b000/spi1@0";
		spi1_pins_b = "/soc@03000000/pinctrl@0300b000/spi1@1";
		spi1_pins_c = "/soc@03000000/pinctrl@0300b000/spi1@2";
		spi2_pins_a = "/soc@03000000/pinctrl@0300b000/spi2@0";
		spi2_pins_b = "/soc@03000000/pinctrl@0300b000/spi2@1";
		spi2_pins_c = "/soc@03000000/pinctrl@0300b000/spi2@2";
		spi3_pins_a = "/soc@03000000/pinctrl@0300b000/spi3@0";
		spi3_pins_b = "/soc@03000000/pinctrl@0300b000/spi3@1";
		spi3_pins_c = "/soc@03000000/pinctrl@0300b000/spi3@2";
		sdc0_pins_a = "/soc@03000000/pinctrl@0300b000/sdc0@0";
		sdc0_pins_b = "/soc@03000000/pinctrl@0300b000/sdc0@1";
		sdc0_pins_c = "/soc@03000000/pinctrl@0300b000/sdc0@2";
		sdc1_pins_a = "/soc@03000000/pinctrl@0300b000/sdc1@0";
		sdc1_pins_b = "/soc@03000000/pinctrl@0300b000/sdc1@1";
		sdc2_pins_a = "/soc@03000000/pinctrl@0300b000/sdc2@0";
		sdc2_pins_b = "/soc@03000000/pinctrl@0300b000/sdc2@1";
		sdc2_pins_c = "/soc@03000000/pinctrl@0300b000/sdc2@2";
		aif2_pins_a = "/soc@03000000/pinctrl@0300b000/aif2@0";
		aif3_pins_a = "/soc@03000000/pinctrl@0300b000/aif3@0";
		aif2_pins_b = "/soc@03000000/pinctrl@0300b000/aif2_sleep@0";
		aif3_pins_b = "/soc@03000000/pinctrl@0300b000/aif3_sleep@0";
		owc0_pins_a = "/soc@03000000/pinctrl@0300b000/owc0@0";
		owc0_pins_b = "/soc@03000000/pinctrl@0300b000/owc0_sleep@0";
		daudio0_pins_a = "/soc@03000000/pinctrl@0300b000/daudio0@0";
		daudio0_pins_b = "/soc@03000000/pinctrl@0300b000/daudio0_sleep@0";
		daudio1_pins_a = "/soc@03000000/pinctrl@0300b000/daudio1@0";
		daudio1_pins_b = "/soc@03000000/pinctrl@0300b000/daudio1_sleep@0";
		csi_mclk0_pins_a = "/soc@03000000/pinctrl@0300b000/csi_mclk0@0";
		csi_mclk0_pins_b = "/soc@03000000/pinctrl@0300b000/csi_mclk0@1";
		csi_mclk1_pins_a = "/soc@03000000/pinctrl@0300b000/csi_mclk1@0";
		csi_mclk1_pins_b = "/soc@03000000/pinctrl@0300b000/csi_mclk1@1";
		csi1_pins_a = "/soc@03000000/pinctrl@0300b000/csi1@0";
		csi1_pins_b = "/soc@03000000/pinctrl@0300b000/csi1@1";
		scr0_pins_a = "/soc@03000000/pinctrl@0300b000/scr0@0";
		scr0_pins_b = "/soc@03000000/pinctrl@0300b000/scr0@1";
		scr0_pins_c = "/soc@03000000/pinctrl@0300b000/scr0@2";
		scr1_pins_a = "/soc@03000000/pinctrl@0300b000/scr1@0";
		scr1_pins_b = "/soc@03000000/pinctrl@0300b000/scr1@1";
		scr1_pins_c = "/soc@03000000/pinctrl@0300b000/scr1@2";
		nand0_pins_a = "/soc@03000000/pinctrl@0300b000/nand0@0";
		nand0_pins_b = "/soc@03000000/pinctrl@0300b000/nand0@1";
		nand0_pins_c = "/soc@03000000/pinctrl@0300b000/nand0@2";
		hdmi_ddc_pin_a = "/soc@03000000/pinctrl@0300b000/hdmi@0";
		hdmi_ddc_pin_b = "/soc@03000000/pinctrl@0300b000/hdmi@1";
		hdmi_cec_pin_a = "/soc@03000000/pinctrl@0300b000/hdmi@2";
		hdmi_cec_pin_b = "/soc@03000000/pinctrl@0300b000/hdmi@3";
		gmac_pins_a = "/soc@03000000/pinctrl@0300b000/gmac@0";
		gmac_pins_b = "/soc@03000000/pinctrl@0300b000/gmac@1";
		dma0 = "/soc@03000000/dma-controller@03002000";
		soc_timer0 = "/soc@03000000/timer@03009000";
		rtc = "/soc@03000000/rtc@07000000";
		wdt = "/soc@03000000/watchdog@030090a0";
		ise = "/soc@03000000/ise@01c10000";
		eise = "/soc@03000000/eise@0x02300000";
		uart0 = "/soc@03000000/uart@05000000";
		uart1 = "/soc@03000000/uart@05000400";
		uart2 = "/soc@03000000/uart@05000800";
		uart3 = "/soc@03000000/uart@05000c00";
		s_owc0 = "/soc@03000000/s_owc@07040400";
		twi0 = "/soc@03000000/twi@0x05002000";
		twi1 = "/soc@03000000/twi@0x05002400";
		twi2 = "/soc@03000000/twi@0x05002800";
		twi3 = "/soc@03000000/twi@0x05002c00";
		twi4 = "/soc@03000000/twi@0x07081400";
		pmu0 = "/soc@03000000/twi@0x07081400/pmu@0";
		powerkey0 = "/soc@03000000/twi@0x07081400/pmu@0/powerkey@0";
		regulator0 = "/soc@03000000/twi@0x07081400/pmu@0/regulators@0";
		reg_dcdc1 = "/soc@03000000/twi@0x07081400/pmu@0/regulators@0/dcdc1";
		reg_dcdc2 = "/soc@03000000/twi@0x07081400/pmu@0/regulators@0/dcdc2";
		reg_dcdc3 = "/soc@03000000/twi@0x07081400/pmu@0/regulators@0/dcdc3";
		reg_dcdc4 = "/soc@03000000/twi@0x07081400/pmu@0/regulators@0/dcdc4";
		reg_aldo1 = "/soc@03000000/twi@0x07081400/pmu@0/regulators@0/aldo1";
		reg_aldo2 = "/soc@03000000/twi@0x07081400/pmu@0/regulators@0/aldo2";
		reg_dldo1 = "/soc@03000000/twi@0x07081400/pmu@0/regulators@0/dldo1";
		reg_dldo2 = "/soc@03000000/twi@0x07081400/pmu@0/regulators@0/dldo2";
		reg_ldo0 = "/soc@03000000/twi@0x07081400/pmu@0/regulators@0/ldo0";
		axp_gpio0 = "/soc@03000000/twi@0x07081400/pmu@0/axp_gpio@0";
		usbc0 = "/soc@03000000/usbc0@0";
		udc = "/soc@03000000/udc-controller@0x05100000";
		ehci0 = "/soc@03000000/ehci0-controller@0x05101000";
		ohci0 = "/soc@03000000/ohci0-controller@0x05101400";
		daudio0 = "/soc@03000000/daudio@0x05090000";
		daudio1 = "/soc@03000000/daudio@0x05091000";
		codec = "/soc@03000000/codec@0x05096000";
		sndcodec = "/soc@03000000/sound@0";
		snddaudio0 = "/soc@03000000/sound@1";
		snddaudio1 = "/soc@03000000/sound@2";
		spi0 = "/soc@03000000/spi@05010000";
		spi1 = "/soc@03000000/spi@05011000";
		spi2 = "/soc@03000000/spi@05012000";
		sdc2 = "/soc@03000000/sdmmc@04022000";
		sdc0 = "/soc@03000000/sdmmc@04020000";
		sdc1 = "/soc@03000000/sdmmc@04021000";
		disp = "/soc@03000000/disp@01000000";
		lcd0 = "/soc@03000000/lcd0@01c0c000";
		soc_tr = "/soc@03000000/tr@01000000";
		g2d = "/soc@03000000/g2d@01480000";
		nna = "/soc@03000000/nna@02400000";
		pwm = "/soc@03000000/pwm@0300a000";
		pwm0 = "/soc@03000000/pwm0@0300a000";
		pwm1 = "/soc@03000000/pwm1@0300a000";
		pwm2 = "/soc@03000000/pwm2@0300a000";
		pwm3 = "/soc@03000000/pwm3@0300a000";
		pwm4 = "/soc@03000000/pwm4@0300a000";
		pwm5 = "/soc@03000000/pwm5@0300a000";
		pwm6 = "/soc@03000000/pwm6@0300a000";
		pwm7 = "/soc@03000000/pwm7@0300a000";
		pwm8 = "/soc@03000000/pwm8@0300a000";
		pwm9 = "/soc@03000000/pwm9@0300a000";
		boot_disp = "/soc@03000000/boot_disp";
		vind0 = "/soc@03000000/vind@0";
		csi0 = "/soc@03000000/vind@0/csi@0";
		csi1 = "/soc@03000000/vind@0/csi@1";
		mipi0 = "/soc@03000000/vind@0/mipi@0";
		isp0 = "/soc@03000000/vind@0/isp@0";
		isp1 = "/soc@03000000/vind@0/isp@1";
		scaler0 = "/soc@03000000/vind@0/scaler@0";
		scaler1 = "/soc@03000000/vind@0/scaler@1";
		scaler2 = "/soc@03000000/vind@0/scaler@2";
		scaler3 = "/soc@03000000/vind@0/scaler@3";
		actuator0 = "/soc@03000000/vind@0/actuator@0";
		flash0 = "/soc@03000000/vind@0/flash@0";
		sensor0 = "/soc@03000000/vind@0/sensor@0";
		sensor1 = "/soc@03000000/vind@0/sensor@1";
		vinc0 = "/soc@03000000/vind@0/vinc@0";
		vinc1 = "/soc@03000000/vind@0/vinc@1";
		vinc2 = "/soc@03000000/vind@0/vinc@2";
		vinc3 = "/soc@03000000/vind@0/vinc@3";
		Vdevice = "/soc@03000000/vdevice@0";
		cryptoengine = "/soc@03000000/ce@1904000";
		nmi = "/soc@03000000/nmi@0x01f00c00";
		sunxi_thermal_sensor = "/soc@03000000/thermal_sensor";
		ths_combine0 = "/soc@03000000/thermal_sensor/ths_combine0";
		ths_combine1 = "/soc@03000000/thermal_sensor/ths_combine1";
		ths_combine2 = "/soc@03000000/thermal_sensor/ths_combine2";
		ths_combine3 = "/soc@03000000/thermal_sensor/ths_combine3";
		cpu_budget_cooling = "/soc@03000000/cpu_budget_cool";
		cpu_trip0 = "/soc@03000000/thermal-zones/cpu_thermal_zone/trips/t0";
		crt_trip = "/soc@03000000/thermal-zones/cpu_thermal_zone/trips/t2";
		ve_crt_trip0 = "/soc@03000000/thermal-zones/ve_thermal_zone/trips/t0";
		isp_crt_trip0 = "/soc@03000000/thermal-zones/isp_thermal_zone/trips/t0";
		ddr_crt_trip0 = "/soc@03000000/thermal-zones/ddr_thermal_zone/trips/t0";
		gpadc = "/soc@03000000/gpadc";
		gmac0 = "/soc@03000000/eth@05020000";
		standby_param = "/soc@03000000/standby_param";
		cpu0 = "/cpus/cpu@0";
		CPU_SLEEP_0 = "/cpus/idle-states/cpu-sleep-0";
		CLUSTER_SLEEP_0 = "/cpus/idle-states/cluster-sleep-0";
		SYS_SLEEP_0 = "/cpus/idle-states/sys-sleep-0";
		dram = "/dram";
		gic = "/interrupt-controller@03020000";
		nmi_intc = "/intc-nmi@07010320";
		wakeupgen = "/interrupt-controller@0";
		sid = "/sunxi-sid@03006000";
		chipid = "/sunxi-chipid@03006200";
		uboot = "/uboot";
		mmu_aw = "/iommu@030f0000";
		mbus0 = "/mbus-controller@047FA000";
		ac200 = "/ac200";
		opp_dvfs_table = "/opp_dvfs_table";
		cpu_opp_l_table0 = "/opp_dvfs_table/opp_l_table0";
		wlan = "/wlan";
		axp2101_parameter = "/axp2101-parameter";
	};
};
